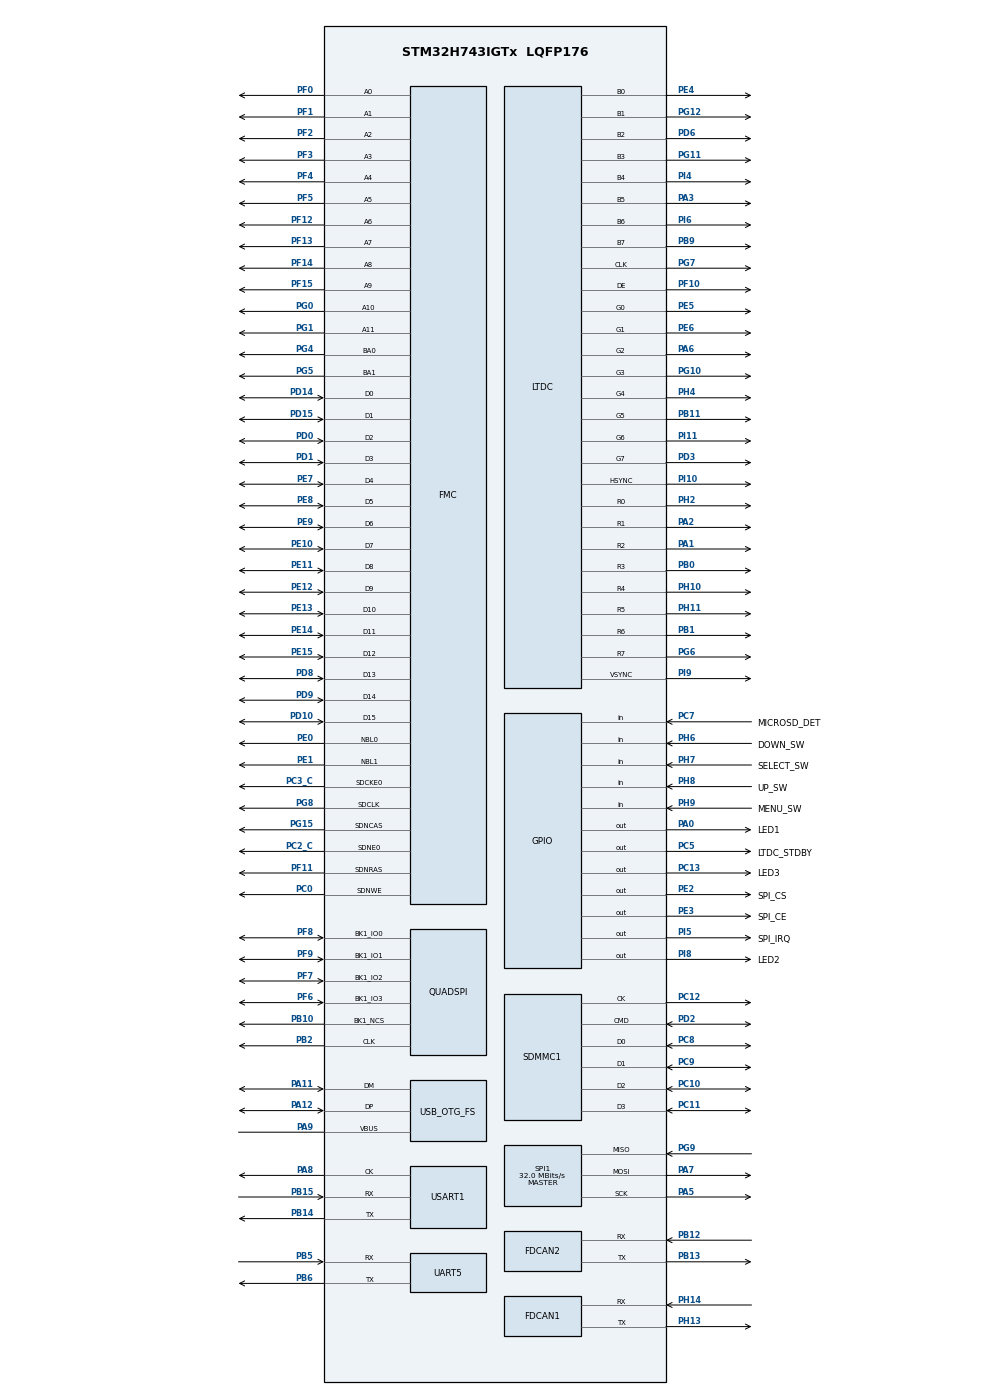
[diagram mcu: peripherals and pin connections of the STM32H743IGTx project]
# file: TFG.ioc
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CORTEX_M7.AccessPermission_S-Cortex_Memory_Protection_Unit_Region1_Settings_S=MPU_REGION_FULL_ACCESS
CORTEX_M7.AccessPermission_S-Cortex_Memory_Protection_Unit_Region2_Settings_S=MPU_REGION_FULL_ACCESS
CORTEX_M7.AccessPermission_S-Cortex_Memory_Protection_Unit_Region3_Settings_S=MPU_REGION_FULL_ACCESS
CORTEX_M7.BaseAddress_S-Cortex_Memory_Protection_Unit_Region1_Settings_S=0x90000000
CORTEX_M7.BaseAddress_S-Cortex_Memory_Protection_Unit_Region2_Settings_S=0xC0000000
CORTEX_M7.BaseAddress_S-Cortex_Memory_Protection_Unit_Region3_Settings_S=0xC0000000
CORTEX_M7.CPU_DCache=Enabled
CORTEX_M7.CPU_ICache=Enabled
CORTEX_M7.DisableExec_S-Cortex_Memory_Protection_Unit_Region1_Settings_S=MPU_INSTRUCTION_ACCESS_DISABLE
CORTEX_M7.DisableExec_S-Cortex_Memory_Protection_Unit_Region2_Settings_S=MPU_INSTRUCTION_ACCESS_DISABLE
CORTEX_M7.DisableExec_S-Cortex_Memory_Protection_Unit_Region3_Settings_S=MPU_INSTRUCTION_ACCESS_DISABLE
CORTEX_M7.Enable_S-Cortex_Memory_Protection_Unit_Region1_Settings_S=MPU_REGION_ENABLE
CORTEX_M7.Enable_S-Cortex_Memory_Protection_Unit_Region2_Settings_S=MPU_REGION_ENABLE
CORTEX_M7.Enable_S-Cortex_Memory_Protection_Unit_Region3_Settings_S=MPU_REGION_ENABLE
CORTEX_M7.IsCacheable_S-Cortex_Memory_Protection_Unit_Region1_Settings_S=MPU_ACCESS_CACHEABLE
CORTEX_M7.IsCacheable_S-Cortex_Memory_Protection_Unit_Region2_Settings_S=MPU_ACCESS_CACHEABLE
CORTEX_M7.IsCacheable_S-Cortex_Memory_Protection_Unit_Region3_Settings_S=MPU_ACCESS_NOT_CACHEABLE
CORTEX_M7.IsShareable_S-Cortex_Memory_Protection_Unit_Region3_Settings_S=MPU_ACCESS_SHAREABLE
CORTEX_M7.Size_S-Cortex_Memory_Protection_Unit_Region1_Settings_S=MPU_REGION_SIZE_256MB
CORTEX_M7.Size_S-Cortex_Memory_Protection_Unit_Region2_Settings_S=MPU_REGION_SIZE_32MB
CORTEX_M7.Size_S-Cortex_Memory_Protection_Unit_Region3_Settings_S=MPU_REGION_SIZE_2MB
CORTEX_M7.SubRegionDisable_S-Cortex_Memory_Protection_Unit_Region1_Settings_S=0x00
CORTEX_M7.default_mode_Activation=1
DMA2D.ColorMode=DMA2D_OUTPUT_RGB565
DMA2D.Mode=DMA2D_M2M
FDCAN1.CalculateBaudRateNominal=500000
FDCAN1.CalculateTimeBitNominal=2000
FDCAN1.CalculateTimeQuantumNominal=125.0
FDCAN1.NominalPrescaler=3
FDCAN1.NominalTimeSeg1=13
FDCAN1.NominalTimeSeg2=2
FDCAN2.AutoRetransmission=ENABLE
FDCAN2.CalculateBaudRateNominal=500000
FDCAN2.CalculateTimeBitNominal=2000
FDCAN2.CalculateTimeQuantumNominal=125.0
FDCAN2.ClockCalibrationCCU=DISABLE
FDCAN2.ExtFiltersNbr=1
FDCAN2.NominalPrescaler=3
FDCAN2.NominalTimeSeg1=13
FDCAN2.NominalTimeSeg2=2
FDCAN2.RxFifo0ElmtsNbr=32
FDCAN2.RxFifo1ElmtsNbr=32
FDCAN2.StdFiltersNbr=2
FDCAN2.TxFifoQueueElmtsNbr=32
FMC.CASLatency1=FMC_SDRAM_CAS_LATENCY_3
FMC.ExitSelfRefreshDelay1=5
FMC.LoadToActiveDelay1=2
FMC.RCDDelay1=2
FMC.RPDelay1=2
FMC.RPDelay2=2
FMC.ReadBurst1=FMC_SDRAM_RBURST_ENABLE
FMC.ReadBurst2=FMC_SDRAM_RBURST_ENABLE
FMC.ReadPipeDelay1=FMC_SDRAM_RPIPE_DELAY_1
FMC.ReadPipeDelay2=FMC_SDRAM_RPIPE_DELAY_1
FMC.RowCycleDelay1=3
FMC.RowCycleDelay2=3
FMC.SDClockPeriod1=FMC_SDRAM_CLOCK_PERIOD_2
FMC.SDClockPeriod2=FMC_SDRAM_CLOCK_PERIOD_2
FMC.SelfRefreshTime1=3
FMC.WriteRecoveryTime1=2
FREERTOS.Tasks01=defaultTask,24,4096,StartDefaultTask,Default,NULL,Dynamic,NULL,NULL;TouchGFXTask,24,4096,TouchGFX_Task,As external,NULL,Dynamic,NULL,NULL
FREERTOS.configTOTAL_HEAP_SIZE=65536
LTDC.ActiveW=800
LTDC.Alpha0_L0=0
LTDC.Alpha_L0=255
LTDC.DEPolarity=LTDC_DEPOLARITY_AH
LTDC.FBStartAdress_L0=0xC0000000
LTDC.HBP=10
LTDC.HFP=246
LTDC.HSync=1
LTDC.ImageHeight_L0=480
LTDC.ImageWidth_L0=800
LTDC.Layers=0
LTDC.PCPolarity=LTDC_PCPOLARITY_IPC
LTDC.PixelFormat_L0=LTDC_PIXEL_FORMAT_RGB565
LTDC.VBP=10
LTDC.VFP=35
LTDC.VSync=1
LTDC.WindowX0_L0=0
LTDC.WindowX1_L0=800
LTDC.WindowY0_L0=0
LTDC.WindowY1_L0=480
Mcu.Family=STM32H7
Mcu.Name=STM32H743IGTx
Mcu.Package=LQFP176
NVIC.DMA2D_IRQn=true\:9\:0\:true\:false\:true\:true\:true\:true\:true
NVIC.FDCAN2_IT0_IRQn=true\:5\:0\:false\:false\:true\:true\:true\:true\:true
NVIC.LTDC_IRQn=true\:9\:0\:true\:false\:true\:true\:true\:true\:true
NVIC.PriorityGroup=NVIC_PRIORITYGROUP_4
PA0.GPIO_Label=LED1
PA0.Signal=GPIO_Output
PA1.Mode=RGB888
PA1.Signal=LTDC_R2
PA11.Mode=Device_Only
PA11.Signal=USB_OTG_FS_DM
PA12.Mode=Device_Only
PA12.Signal=USB_OTG_FS_DP
PA13\ (JTMS/SWDIO).Mode=Serial_Wire
PA13\ (JTMS/SWDIO).Signal=DEBUG_JTMS-SWDIO
PA14\ (JTCK/SWCLK).Mode=Serial_Wire
PA14\ (JTCK/SWCLK).Signal=DEBUG_JTCK-SWCLK
PA2.Mode=RGB888
PA2.Signal=LTDC_R1
PA3.Mode=RGB888
PA3.Signal=LTDC_B5
PA5.Mode=Full_Duplex_Master
PA5.Signal=SPI1_SCK
PA6.Mode=RGB888
PA6.Signal=LTDC_G2
PA7.Mode=Full_Duplex_Master
PA7.Signal=SPI1_MOSI
PA8.Mode=Synchronous
PA8.Signal=USART1_CK
PA9.Mode=Activate_VBUS
PA9.Signal=USB_OTG_FS_VBUS
PB0.Mode=RGB888
PB0.Signal=LTDC_R3
PB1.Mode=RGB888
PB1.Signal=LTDC_R6
PB10.Mode=Single Bank 1
PB10.Signal=QUADSPI_BK1_NCS
PB11.Mode=RGB888
PB11.Signal=LTDC_G5
PB12.Mode=FDCAN_Activate
PB12.Signal=FDCAN2_RX
PB13.Mode=FDCAN_Activate
PB13.Signal=FDCAN2_TX
PB14.Mode=Synchronous
PB14.Signal=USART1_TX
PB15.Mode=Synchronous
PB15.Signal=USART1_RX
PB2.Mode=Single Bank 1
PB2.Signal=QUADSPI_CLK
PB5.Mode=Asynchronous
PB5.Signal=UART5_RX
PB6.Mode=Asynchronous
PB6.Signal=UART5_TX
PB9.Mode=RGB888
PB9.Signal=LTDC_B7
PC0.Signal=FMC_SDNWE
PC10.Mode=SD_4_bits_Wide_bus
PC10.Signal=SDMMC1_D2
PC11.Mode=SD_4_bits_Wide_bus
PC11.Signal=SDMMC1_D3
PC12.Mode=SD_4_bits_Wide_bus
PC12.Signal=SDMMC1_CK
PC13.GPIO_Label=LED3
PC13.Signal=GPIO_Output
PC2_C.Mode=SdramChipSelect1_1
PC2_C.Signal=FMC_SDNE0
PC3_C.Mode=SdramChipSelect1_1
PC3_C.Signal=FMC_SDCKE0
PC5.GPIO_Label=LTDC_STDBY
PC5.Signal=GPIO_Output
PC7.GPIO_Label=MICROSD_DET
PC7.Signal=GPIO_Input
PC8.Mode=SD_4_bits_Wide_bus
PC8.Signal=SDMMC1_D0
PC9.Mode=SD_4_bits_Wide_bus
PC9.Signal=SDMMC1_D1
PD0.Signal=FMC_D2_DA2
PD1.Signal=FMC_D3_DA3
PD10.Signal=FMC_D15_DA15
PD14.Signal=FMC_D0_DA0
PD15.Signal=FMC_D1_DA1
PD2.Mode=SD_4_bits_Wide_bus
PD2.Signal=SDMMC1_CMD
PD3.Mode=RGB888
PD3.Signal=LTDC_G7
PD6.Mode=RGB888
PD6.Signal=LTDC_B2
PD8.Signal=FMC_D13_DA13
PD9.Signal=FMC_D14_DA14
PE0.Signal=FMC_NBL0
PE1.Signal=FMC_NBL1
PE10.Signal=FMC_D7_DA7
PE11.Signal=FMC_D8_DA8
PE12.Signal=FMC_D9_DA9
PE13.Signal=FMC_D10_DA10
PE14.Signal=FMC_D11_DA11
PE15.Signal=FMC_D12_DA12
PE2.GPIO_Label=SPI_CS
PE2.Signal=GPIO_Output
PE3.GPIO_Label=SPI_CE
PE3.Signal=GPIO_Output
PE4.Mode=RGB888
PE4.Signal=LTDC_B0
PE5.Mode=RGB888
PE5.Signal=LTDC_G0
PE6.Mode=RGB888
PE6.Signal=LTDC_G1
PE7.Signal=FMC_D4_DA4
PE8.Signal=FMC_D5_DA5
PE9.Signal=FMC_D6_DA6
PF0.Signal=FMC_A0
PF1.Signal=FMC_A1
PF10.Mode=RGB888
PF10.Signal=LTDC_DE
PF11.Signal=FMC_SDNRAS
PF12.Signal=FMC_A6
PF13.Signal=FMC_A7
PF14.Signal=FMC_A8
PF15.Signal=FMC_A9
PF2.Signal=FMC_A2
PF3.Signal=FMC_A3
PF4.Signal=FMC_A4
PF5.Signal=FMC_A5
PF6.Mode=Single Bank 1
PF6.Signal=QUADSPI_BK1_IO3
PF7.Mode=Single Bank 1
PF7.Signal=QUADSPI_BK1_IO2
PF8.Mode=Single Bank 1
PF8.Signal=QUADSPI_BK1_IO0
PF9.Mode=Single Bank 1
PF9.Signal=QUADSPI_BK1_IO1
PG0.Signal=FMC_A10
PG1.Signal=FMC_A11
PG10.Mode=RGB888
PG10.Signal=LTDC_G3
PG11.Mode=RGB888
PG11.Signal=LTDC_B3
PG12.Mode=RGB888
PG12.Signal=LTDC_B1
PG15.Signal=FMC_SDNCAS
PG4.Signal=FMC_A14_BA0
PG5.Signal=FMC_A15_BA1
PG6.Mode=RGB888
PG6.Signal=LTDC_R7
PG7.Mode=RGB888
PG7.Signal=LTDC_CLK
PG8.Signal=FMC_SDCLK
PG9.Mode=Full_Duplex_Master
PG9.Signal=SPI1_MISO
PH0-OSC_IN\ (PH0).Mode=HSE-External-Oscillator
PH0-OSC_IN\ (PH0).Signal=RCC_OSC_IN
PH1-OSC_OUT\ (PH1).Mode=HSE-External-Oscillator
PH1-OSC_OUT\ (PH1).Signal=RCC_OSC_OUT
PH10.Mode=RGB888
PH10.Signal=LTDC_R4
PH11.Mode=RGB888
PH11.Signal=LTDC_R5
PH13.Mode=FDCAN_Activate
PH13.Signal=FDCAN1_TX
PH14.Mode=FDCAN_Activate
PH14.Signal=FDCAN1_RX
PH2.Mode=RGB888
PH2.Signal=LTDC_R0
PH4.Mode=RGB888
PH4.Signal=LTDC_G4
PH6.GPIO_Label=DOWN_SW
PH6.GPIO_PuPd=GPIO_PULLDOWN
PH6.Signal=GPIO_Input
PH7.GPIO_Label=SELECT_SW
PH7.GPIO_PuPd=GPIO_PULLDOWN
PH7.Signal=GPIO_Input
PH8.GPIO_Label=UP_SW
PH8.GPIO_PuPd=GPIO_PULLDOWN
PH8.Signal=GPIO_Input
PH9.GPIO_Label=MENU_SW
PH9.GPIO_PuPd=GPIO_PULLDOWN
PH9.Signal=GPIO_Input
PI10.Mode=RGB888
PI10.Signal=LTDC_HSYNC
PI11.Mode=RGB888
PI11.Signal=LTDC_G6
PI4.Mode=RGB888
PI4.Signal=LTDC_B4
PI5.GPIO_Label=SPI_IRQ
PI5.Signal=GPIO_Output
PI6.Mode=RGB888
PI6.Signal=LTDC_B6
PI8.GPIO_Label=LED2
PI8.Signal=GPIO_Output
PI9.Mode=RGB888
PI9.Signal=LTDC_VSYNC
ProjectManager.HeapSize=0x200
ProjectManager.StackSize=0x400
ProjectManager.TargetToolchain=STM32CubeIDE
QUADSPI.ChipSelectHighTime=QSPI_CS_HIGH_TIME_2_CYCLE
QUADSPI.ClockPrescaler=3
QUADSPI.FifoThreshold=4
QUADSPI.FlashSize=23
RCC.ADCFreq_Value=129000000
RCC.APB1Freq_Value=60000000
RCC.APB2Freq_Value=60000000
RCC.APB3Freq_Value=60000000
RCC.APB4Freq_Value=60000000
RCC.CortexFreq_Value=240000000
RCC.D1PPRE=RCC_APB3_DIV2
RCC.D2PPRE1=RCC_APB1_DIV2
RCC.D2PPRE2=RCC_APB2_DIV2
RCC.D3PPRE=RCC_APB4_DIV2
RCC.DIVM1=8
RCC.DIVM3=4
RCC.DIVN1=60
RCC.DIVN3=20
RCC.DIVQ1=4
RCC.DIVR2=6
RCC.DIVR3=11
RCC.HCLKFreq_Value=120000000
RCC.HPRE=RCC_HCLK_DIV2
RCC.HSE_VALUE=24000000
RCC.PLL2FRACN=0
RCC.PLL3FRACN=0
RCC.PLLFRACN=0
RCC.SDMMC1CLockSelection=RCC_SDMMCCLKSOURCE_PLL2
RCC.SPI123CLockSelection=RCC_SPI123CLKSOURCE_CLKP
RCC.SYSCLKFreq_VALUE=240000000
RCC.SYSCLKSource=RCC_SYSCLKSOURCE_PLLCLK
RCC.USART16CLockSelection=RCC_USART16CLKSOURCE_CSI
RCC.USART234578CLockSelection=RCC_USART234578CLKSOURCE_CSI
RCC.USBCLockSelection=RCC_USBCLKSOURCE_HSI48
RCC.USBFreq_Value=48000000
SDMMC1.ClockDiv=2
SH.FMC_A0.0=FMC_A0,12b-sda1
SH.FMC_A1.0=FMC_A1,12b-sda1
SH.FMC_A10.0=FMC_A10,12b-sda1
SH.FMC_A11.0=FMC_A11,12b-sda1
SH.FMC_A14_BA0.0=FMC_BA0,FourSdramBanks1
SH.FMC_A15_BA1.0=FMC_BA1,FourSdramBanks1
SH.FMC_A2.0=FMC_A2,12b-sda1
SH.FMC_A3.0=FMC_A3,12b-sda1
SH.FMC_A4.0=FMC_A4,12b-sda1
SH.FMC_A5.0=FMC_A5,12b-sda1
SH.FMC_A6.0=FMC_A6,12b-sda1
SH.FMC_A7.0=FMC_A7,12b-sda1
SH.FMC_A8.0=FMC_A8,12b-sda1
SH.FMC_A9.0=FMC_A9,12b-sda1
SH.FMC_D0_DA0.0=FMC_D0,sd-16b-d1
SH.FMC_D10_DA10.0=FMC_D10,sd-16b-d1
SH.FMC_D11_DA11.0=FMC_D11,sd-16b-d1
SH.FMC_D12_DA12.0=FMC_D12,sd-16b-d1
SH.FMC_D13_DA13.0=FMC_D13,sd-16b-d1
SH.FMC_D14_DA14.0=FMC_D14,sd-16b-d1
SH.FMC_D15_DA15.0=FMC_D15,sd-16b-d1
SH.FMC_D1_DA1.0=FMC_D1,sd-16b-d1
SH.FMC_D2_DA2.0=FMC_D2,sd-16b-d1
SH.FMC_D3_DA3.0=FMC_D3,sd-16b-d1
SH.FMC_D4_DA4.0=FMC_D4,sd-16b-d1
SH.FMC_D5_DA5.0=FMC_D5,sd-16b-d1
SH.FMC_D6_DA6.0=FMC_D6,sd-16b-d1
SH.FMC_D7_DA7.0=FMC_D7,sd-16b-d1
SH.FMC_D8_DA8.0=FMC_D8,sd-16b-d1
SH.FMC_D9_DA9.0=FMC_D9,sd-16b-d1
SH.FMC_NBL0.0=FMC_NBL0,Sd2ByteEnable1
SH.FMC_NBL1.0=FMC_NBL1,Sd2ByteEnable1
SH.FMC_SDCLK.0=FMC_SDCLK,12b-sda1
SH.FMC_SDNCAS.0=FMC_SDNCAS,12b-sda1
SH.FMC_SDNRAS.0=FMC_SDNRAS,12b-sda1
SH.FMC_SDNWE.0=FMC_SDNWE,12b-sda1
SPI1.CalculateBaudRate=32.0 MBits/s
SPI1.Direction=SPI_DIRECTION_2LINES
SPI1.Mode=SPI_MODE_MASTER
SPI1.VirtualType=VM_MASTER
STMicroelectronics.X-CUBE-TOUCHGFX.4.25.0.ApplicationCcGraphicsJjApplication=TouchGFXOoGenerator
STMicroelectronics.X-CUBE-TOUCHGFX.4.25.0.tgfx_buffering_strategy=Double
STMicroelectronics.X-CUBE-TOUCHGFX.4.25.0.tgfx_display_interface=disp_ltdc
STMicroelectronics.X-CUBE-TOUCHGFX.4.25.0.tgfx_hardware_accelerator=dma_2d
STMicroelectronics.X-CUBE-TOUCHGFX.4.25.0.tgfx_vsync=vsync_ltdc
STMicroelectronics.X-CUBE-TOUCHGFX.4.25.0_IsPackSelfContextualization=true
USART1.VirtualMode-Synchronous=VM_SYNC
USB_OTG_FS.VirtualMode=Device_Only
VP_CRC_VS_CRC.Mode=CRC_Activate
VP_DMA2D_VS_DMA2D.Mode=DMA2D_Activate
VP_FATFS_VS_SDIO.Mode=SDIO
VP_FREERTOS_VS_CMSIS_V2.Mode=CMSIS_V2
VP_JPEG_VS_JPEG.Mode=JPEG_Activate
VP_MEMORYMAP_VS_MEMORYMAP.Mode=CurAppReg
VP_STMicroelectronics.X-CUBE-TOUCHGFX_VS_GraphicsJjApplication_4.25.0.Mode=GraphicsJjApplication
board=custom

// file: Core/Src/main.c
/* USER CODE BEGIN Header */
/**
  ******************************************************************************
  * @file           : main.c
  * @brief          : Main program body
  ******************************************************************************
  * @attention
  *
  * Copyright (c) 2026 STMicroelectronics.
  * All rights reserved.
  *
  * This software is licensed under terms that can be found in the LICENSE file
  * in the root directory of this software component.
  * If no LICENSE file comes with this software, it is provided AS-IS.
  *
  ******************************************************************************
  */
/* USER CODE END Header */
#include "main.h"
#include "cmsis_os.h"
#include "crc.h"
#include "dma2d.h"
#include "fatfs.h"
#include "fdcan.h"
#include "jpeg.h"
#include "ltdc.h"
#include "memorymap.h"
#include "quadspi.h"
#include "sdmmc.h"
#include "spi.h"
#include "usart.h"
#include "usb_otg.h"
#include "gpio.h"
#include "fmc.h"
#include "app_touchgfx.h"
#include <stdio.h>

/* USER CODE BEGIN Includes */
#include <string.h>

extern uint8_t ltdc_init_ok;
extern uint8_t ltdc_init_fail_step;
extern uint8_t sdmmc1_init_ok;
volatile uint8_t g_sd_preos_done = 0U;
volatile uint8_t g_sd_preos_ok = 0U;

/* USER CODE END Includes */

/* USER CODE BEGIN PD */
#define QSPI_CMD_JEDEC_ID                ((uint8_t)0x9F)
#define QSPI_CMD_READ_DATA               ((uint8_t)0x03)
#define QSPI_CMD_FAST_READ               ((uint8_t)0x0B)
#define QSPI_CMD_WRITE_ENABLE            ((uint8_t)0x06)
#define QSPI_CMD_READ_STATUS_REG         ((uint8_t)0x05)
#define QSPI_CMD_PAGE_PROGRAM            ((uint8_t)0x02)
#define QSPI_CMD_SECTOR_ERASE_4K         ((uint8_t)0x20)
#define QSPI_STATUS_WIP                  ((uint8_t)0x01)
#define QSPI_STATUS_WEL                  ((uint8_t)0x02)
#define MT25QL128_JEDEC_MFR              ((uint8_t)0x20)
#define MT25QL128_JEDEC_TYPE             ((uint8_t)0xBA)
#define MT25QL128_JEDEC_CAP              ((uint8_t)0x18)
#define QSPI_TIMEOUT_MS                  ((uint32_t)2000U)
#define QSPI_SECTOR_SIZE                 ((uint32_t)4096U)
#define QSPI_PAGE_SIZE                   ((uint32_t)256U)

#define LCD_WIDTH                        ((uint32_t)800U)
#define LCD_HEIGHT                       ((uint32_t)480U)
#define LCD_BPP_BYTES                    ((uint32_t)2U)
#define LCD_FB_SIZE_BYTES                (LCD_WIDTH * LCD_HEIGHT * LCD_BPP_BYTES)
#define LCD_FB_ADDRESS                   ((uint32_t)0xC0000000U)
#define LCD_FB_ADDRESS_ALT               (LCD_FB_ADDRESS + LCD_FB_SIZE_BYTES)
#define LCD_FB_MPU_REGION_SIZE           MPU_REGION_SIZE_2MB
#define LTDC_FORCE_DIRECT_RED_FRAME      0U

/* USER CODE END PD */

/* USER CODE BEGIN PV */
uint8_t qspi_test_ok = 0U;
uint8_t ltdc_fail_code = 0U;
uint8_t touchgfx_assets_ok = 0U;

/* USER CODE END PV */

void SystemClock_Config(void);
void PeriphCommonClock_Config(void);
static void MPU_Config(void);
void MX_FREERTOS_Init(void);
/* USER CODE BEGIN PFP */
static uint8_t QSPI_QuickTest(void);
static uint8_t QSPI_WriteEnable(void);
static uint8_t QSPI_WaitReady(uint32_t timeout_ms);
static uint8_t QSPI_Read(uint32_t address, uint8_t *buffer, uint32_t length);
static uint8_t QSPI_PageProgram(uint32_t address, const uint8_t *buffer, uint32_t length);
static uint8_t QSPI_SectorErase(uint32_t address);
static uint8_t QSPI_ProgramBuffer(uint32_t address, const uint8_t *buffer, uint32_t length);
static uint8_t QSPI_EnableMemoryMappedMode(void);
static uint8_t TouchGFX_AssetsPresent(void);
static void TouchGFX_LogAssetProbe(void);

/* USER CODE END PFP */

/* USER CODE BEGIN 0 */
static uint8_t qspi_backup_sector[QSPI_SECTOR_SIZE];
static uint8_t qspi_test_pattern[QSPI_PAGE_SIZE];
static uint8_t qspi_verify_page[QSPI_PAGE_SIZE];
extern uint8_t __extflash_start__;
extern uint8_t __extflash_end__;

__attribute__((weak)) void MX_FATFS_Init(void)
{
}

__attribute__((weak)) void MX_TouchGFX_Init(void)
{
}

__attribute__((weak)) void MX_TouchGFX_PreOSInit(void)
{
}

__attribute__((weak)) osStatus_t osKernelInitialize(void)
{
  return osOK;
}

__attribute__((weak)) osStatus_t osKernelStart(void)
{
  return osOK;
}

__attribute__((weak)) void MX_FREERTOS_Init(void)
{
}

static uint8_t QSPI_WriteEnable(void)
{
  QSPI_CommandTypeDef s_command = {0};
  QSPI_AutoPollingTypeDef s_config = {0};

  s_command.InstructionMode = QSPI_INSTRUCTION_1_LINE;
  s_command.Instruction = QSPI_CMD_WRITE_ENABLE;
  s_command.AddressMode = QSPI_ADDRESS_NONE;
  s_command.AlternateByteMode = QSPI_ALTERNATE_BYTES_NONE;
  s_command.DataMode = QSPI_DATA_NONE;
  s_command.DummyCycles = 0;
  s_command.DdrMode = QSPI_DDR_MODE_DISABLE;
  s_command.DdrHoldHalfCycle = QSPI_DDR_HHC_ANALOG_DELAY;
  s_command.SIOOMode = QSPI_SIOO_INST_EVERY_CMD;

  if (HAL_QSPI_Command(&hqspi, &s_command, QSPI_TIMEOUT_MS) != HAL_OK)
  {
    return 0U;
  }

  s_command.Instruction = QSPI_CMD_READ_STATUS_REG;
  s_command.DataMode = QSPI_DATA_1_LINE;
  s_command.NbData = 1;

  s_config.Match = QSPI_STATUS_WEL;
  s_config.Mask = QSPI_STATUS_WEL;
  s_config.MatchMode = QSPI_MATCH_MODE_AND;
  s_config.StatusBytesSize = 1;
  s_config.Interval = 0x10;
  s_config.AutomaticStop = QSPI_AUTOMATIC_STOP_ENABLE;

  if (HAL_QSPI_AutoPolling(&hqspi, &s_command, &s_config, QSPI_TIMEOUT_MS) != HAL_OK)
  {
    return 0U;
  }

  return 1U;
}

static uint8_t QSPI_WaitReady(uint32_t timeout_ms)
{
  QSPI_CommandTypeDef s_command = {0};
  QSPI_AutoPollingTypeDef s_config = {0};

  s_command.InstructionMode = QSPI_INSTRUCTION_1_LINE;
  s_command.Instruction = QSPI_CMD_READ_STATUS_REG;
  s_command.AddressMode = QSPI_ADDRESS_NONE;
  s_command.AlternateByteMode = QSPI_ALTERNATE_BYTES_NONE;
  s_command.DataMode = QSPI_DATA_1_LINE;
  s_command.DummyCycles = 0;
  s_command.NbData = 1;
  s_command.DdrMode = QSPI_DDR_MODE_DISABLE;
  s_command.DdrHoldHalfCycle = QSPI_DDR_HHC_ANALOG_DELAY;
  s_command.SIOOMode = QSPI_SIOO_INST_EVERY_CMD;

  s_config.Match = 0;
  s_config.Mask = QSPI_STATUS_WIP;
  s_config.MatchMode = QSPI_MATCH_MODE_AND;
  s_config.StatusBytesSize = 1;
  s_config.Interval = 0x10;
  s_config.AutomaticStop = QSPI_AUTOMATIC_STOP_ENABLE;

  if (HAL_QSPI_AutoPolling(&hqspi, &s_command, &s_config, timeout_ms) != HAL_OK)
  {
    return 0U;
  }

  return 1U;
}

static uint8_t QSPI_Read(uint32_t address, uint8_t *buffer, uint32_t length)
{
  QSPI_CommandTypeDef s_command = {0};

  s_command.InstructionMode = QSPI_INSTRUCTION_1_LINE;
  s_command.Instruction = QSPI_CMD_READ_DATA;
  s_command.AddressMode = QSPI_ADDRESS_1_LINE;
  s_command.AddressSize = QSPI_ADDRESS_24_BITS;
  s_command.Address = address;
  s_command.AlternateByteMode = QSPI_ALTERNATE_BYTES_NONE;
  s_command.DataMode = QSPI_DATA_1_LINE;
  s_command.DummyCycles = 0;
  s_command.NbData = length;
  s_command.DdrMode = QSPI_DDR_MODE_DISABLE;
  s_command.DdrHoldHalfCycle = QSPI_DDR_HHC_ANALOG_DELAY;
  s_command.SIOOMode = QSPI_SIOO_INST_EVERY_CMD;

  if (HAL_QSPI_Command(&hqspi, &s_command, QSPI_TIMEOUT_MS) != HAL_OK)
  {
    return 0U;
  }

  if (HAL_QSPI_Receive(&hqspi, buffer, QSPI_TIMEOUT_MS) != HAL_OK)
  {
    return 0U;
  }

  return 1U;
}

static uint8_t QSPI_PageProgram(uint32_t address, const uint8_t *buffer, uint32_t length)
{
  QSPI_CommandTypeDef s_command = {0};

  if ((length == 0U) || (length > QSPI_PAGE_SIZE))
  {
    return 0U;
  }

  if (QSPI_WriteEnable() == 0U)
  {
    return 0U;
  }

  s_command.InstructionMode = QSPI_INSTRUCTION_1_LINE;
  s_command.Instruction = QSPI_CMD_PAGE_PROGRAM;
  s_command.AddressMode = QSPI_ADDRESS_1_LINE;
  s_command.AddressSize = QSPI_ADDRESS_24_BITS;
  s_command.Address = address;
  s_command.AlternateByteMode = QSPI_ALTERNATE_BYTES_NONE;
  s_command.DataMode = QSPI_DATA_1_LINE;
  s_command.DummyCycles = 0;
  s_command.NbData = length;
  s_command.DdrMode = QSPI_DDR_MODE_DISABLE;
  s_command.DdrHoldHalfCycle = QSPI_DDR_HHC_ANALOG_DELAY;
  s_command.SIOOMode = QSPI_SIOO_INST_EVERY_CMD;

  if (HAL_QSPI_Command(&hqspi, &s_command, QSPI_TIMEOUT_MS) != HAL_OK)
  {
    return 0U;
  }

  if (HAL_QSPI_Transmit(&hqspi, (uint8_t *)buffer, QSPI_TIMEOUT_MS) != HAL_OK)
  {
    return 0U;
  }

  return QSPI_WaitReady(QSPI_TIMEOUT_MS);
}

static uint8_t QSPI_SectorErase(uint32_t address)
{
  QSPI_CommandTypeDef s_command = {0};

  if (QSPI_WriteEnable() == 0U)
  {
    return 0U;
  }

  s_command.InstructionMode = QSPI_INSTRUCTION_1_LINE;
  s_command.Instruction = QSPI_CMD_SECTOR_ERASE_4K;
  s_command.AddressMode = QSPI_ADDRESS_1_LINE;
  s_command.AddressSize = QSPI_ADDRESS_24_BITS;
  s_command.Address = address;
  s_command.AlternateByteMode = QSPI_ALTERNATE_BYTES_NONE;
  s_command.DataMode = QSPI_DATA_NONE;
  s_command.DummyCycles = 0;
  s_command.DdrMode = QSPI_DDR_MODE_DISABLE;
  s_command.DdrHoldHalfCycle = QSPI_DDR_HHC_ANALOG_DELAY;
  s_command.SIOOMode = QSPI_SIOO_INST_EVERY_CMD;

  if (HAL_QSPI_Command(&hqspi, &s_command, QSPI_TIMEOUT_MS) != HAL_OK)
  {
    return 0U;
  }

  return QSPI_WaitReady(8000U);
}

static uint8_t QSPI_ProgramBuffer(uint32_t address, const uint8_t *buffer, uint32_t length)
{
  uint32_t offset = 0U;
  uint32_t chunk = 0U;

  while (offset < length)
  {
    chunk = length - offset;
    if (chunk > QSPI_PAGE_SIZE)
    {
      chunk = QSPI_PAGE_SIZE;
    }

    if (QSPI_PageProgram(address + offset, &buffer[offset], chunk) == 0U)
    {
      return 0U;
    }

    offset += chunk;
  }

  return 1U;
}

static uint8_t QSPI_QuickTest(void)
{
  QSPI_CommandTypeDef s_command = {0};
  uint8_t jedec_id[3] = {0};
  uint32_t flash_size_bytes = 0U;
  uint32_t test_sector_addr = 0U;

  s_command.InstructionMode = QSPI_INSTRUCTION_1_LINE;
  s_command.Instruction = 0x9FU;
  s_command.AddressMode = QSPI_ADDRESS_NONE;
  s_command.AlternateByteMode = QSPI_ALTERNATE_BYTES_NONE;
  s_command.DataMode = QSPI_DATA_1_LINE;
  s_command.DummyCycles = 0;
  s_command.NbData = 3;
  s_command.DdrMode = QSPI_DDR_MODE_DISABLE;
  s_command.DdrHoldHalfCycle = QSPI_DDR_HHC_ANALOG_DELAY;
  s_command.SIOOMode = QSPI_SIOO_INST_EVERY_CMD;

  if (HAL_QSPI_Command(&hqspi, &s_command, 1000U) != HAL_OK)
  {
    return 0U;
  }

  if (HAL_QSPI_Receive(&hqspi, jedec_id, 1000U) != HAL_OK)
  {
    return 0U;
  }

  if ((jedec_id[0] == 0x00U) || (jedec_id[0] == 0xFFU))
  {
    return 0U;
  }

  if ((jedec_id[1] == 0x00U) && (jedec_id[2] == 0x00U))
  {
    return 0U;
  }

  if ((jedec_id[0] != MT25QL128_JEDEC_MFR) ||
      (jedec_id[1] != MT25QL128_JEDEC_TYPE) ||
      (jedec_id[2] != MT25QL128_JEDEC_CAP))
  {
    return 0U;
  }

  if ((jedec_id[2] < 0x10U) || (jedec_id[2] > 0x25U))
  {
    return 0U;
  }

  flash_size_bytes = (1UL << jedec_id[2]);
  if (flash_size_bytes < (QSPI_SECTOR_SIZE * 4U))
  {
    return 0U;
  }

  test_sector_addr = flash_size_bytes - (QSPI_SECTOR_SIZE * 2U);

  if (QSPI_Read(test_sector_addr, qspi_backup_sector, QSPI_SECTOR_SIZE) == 0U)
  {
    return 0U;
  }

  for (uint32_t i = 0U; i < QSPI_PAGE_SIZE; i++)
  {
    qspi_test_pattern[i] = (uint8_t)(i ^ 0x5AU);
  }

  if (QSPI_SectorErase(test_sector_addr) == 0U)
  {
    return 0U;
  }

  if (QSPI_PageProgram(test_sector_addr, qspi_test_pattern, QSPI_PAGE_SIZE) == 0U)
  {
    return 0U;
  }

  if (QSPI_Read(test_sector_addr, qspi_verify_page, QSPI_PAGE_SIZE) == 0U)
  {
    return 0U;
  }

  if (memcmp(qspi_test_pattern, qspi_verify_page, QSPI_PAGE_SIZE) != 0)
  {
    return 0U;
  }

  if (QSPI_SectorErase(test_sector_addr) == 0U)
  {
    return 0U;
  }

  if (QSPI_ProgramBuffer(test_sector_addr, qspi_backup_sector, QSPI_SECTOR_SIZE) == 0U)
  {
    return 0U;
  }

  return 1U;
}

static uint8_t QSPI_EnableMemoryMappedMode(void)
{
  QSPI_CommandTypeDef s_command = {0};
  QSPI_MemoryMappedTypeDef s_mem_mapped_cfg = {0};

  s_command.InstructionMode = QSPI_INSTRUCTION_1_LINE;
  s_command.Instruction = QSPI_CMD_FAST_READ;
  s_command.AddressMode = QSPI_ADDRESS_1_LINE;
  s_command.AddressSize = QSPI_ADDRESS_24_BITS;
  s_command.Address = 0U;
  s_command.AlternateByteMode = QSPI_ALTERNATE_BYTES_NONE;
  s_command.DataMode = QSPI_DATA_1_LINE;
  s_command.DummyCycles = 8;
  s_command.NbData = 0U;
  s_command.DdrMode = QSPI_DDR_MODE_DISABLE;
  s_command.DdrHoldHalfCycle = QSPI_DDR_HHC_ANALOG_DELAY;
  s_command.SIOOMode = QSPI_SIOO_INST_EVERY_CMD;

  s_mem_mapped_cfg.TimeOutActivation = QSPI_TIMEOUT_COUNTER_DISABLE;
  s_mem_mapped_cfg.TimeOutPeriod = 0U;

  if (HAL_QSPI_MemoryMapped(&hqspi, &s_command, &s_mem_mapped_cfg) != HAL_OK)
  {
    return 0U;
  }

  return 1U;
}

static uint8_t TouchGFX_AssetsPresent(void)
{
  volatile const uint8_t *ext = &__extflash_start__;
  uint32_t ext_size = (uint32_t)(&__extflash_end__ - &__extflash_start__);
  uint32_t sample = 0U;
  uint32_t non_ff = 0U;

  if (ext_size == 0U)
  {
    return 0U;
  }

  sample = (ext_size >= 256U) ? 256U : ext_size;

  for (uint32_t i = 0U; i < sample; i++)
  {
    if (ext[i] != 0xFFU)
    {
      non_ff++;
    }
  }

  return (non_ff > 8U) ? 1U : 0U;
}

static void TouchGFX_LogAssetProbe(void)
{
  volatile const uint8_t *ext = &__extflash_start__;
  uint32_t ext_size = (uint32_t)(&__extflash_end__ - &__extflash_start__);
  char buffer[192];

  if (huart5.gState == HAL_UART_STATE_RESET)
  {
    return;
  }

  if (ext_size < 16U)
  {
    (void)snprintf(buffer,
                   sizeof(buffer),
                   "[BOOT] extflash size=%lu bytes (too small for probe)\r\n",
                   (unsigned long)ext_size);
    Debug_LogUart5(buffer);
    return;
  }

  (void)snprintf(buffer,
                 sizeof(buffer),
                 "[BOOT] asset section @%08lX size=%lu sample=%02X %02X %02X %02X %02X %02X %02X %02X %02X %02X %02X %02X %02X %02X %02X %02X\r\n",
                 (unsigned long)ext,
                 (unsigned long)ext_size,
                 ext[0], ext[1], ext[2], ext[3],
                 ext[4], ext[5], ext[6], ext[7],
                 ext[8], ext[9], ext[10], ext[11],
                 ext[12], ext[13], ext[14], ext[15]);
  Debug_LogUart5(buffer);
}

  /* Disable D-Cache for a clean test — same approach as HW diagnostic */
/* USER CODE END 0 */

int main(void)
{

  /* USER CODE BEGIN 1 */
  /* ---- Raw LED init via registers (before HAL, before anything) ---- */
  /* LED1=PA0, LED2=PI8, LED3=PC13 */
  RCC->AHB4ENR |= RCC_AHB4ENR_GPIOAEN | RCC_AHB4ENR_GPIOCEN | RCC_AHB4ENR_GPIOIEN;
  __DSB(); __NOP(); __NOP();
  /* PA0 = output */
  GPIOA->MODER = (GPIOA->MODER & ~(3U << (0*2))) | (1U << (0*2));
  /* PC13 = output */
  GPIOC->MODER = (GPIOC->MODER & ~(3U << (13*2))) | (1U << (13*2));
  /* PI8 = output */
  GPIOI->MODER = (GPIOI->MODER & ~(3U << (8*2))) | (1U << (8*2));
  /* All LEDs OFF */
  GPIOA->BSRR = (1U << (0+16));  /* LED1 OFF */
  GPIOI->BSRR = (1U << (8+16));  /* LED2 OFF */
  GPIOC->BSRR = (1U << (13+16)); /* LED3 OFF */
  /* USER CODE END 1 */

  /* MPU Configuration--------------------------------------------------------*/
  MPU_Config();

  /* Enable the CPU Cache */

  /* Enable I-Cache---------------------------------------------------------*/
  SCB_EnableICache();

  /* Enable D-Cache---------------------------------------------------------*/
  SCB_EnableDCache();

  /* MCU Configuration--------------------------------------------------------*/

  /* Reset of all peripherals, Initializes the Flash interface and the Systick. */
  HAL_Init();

  /* USER CODE BEGIN Init */
  /* LED1 ON = HAL_Init passed */
  GPIOA->BSRR = (1U << 0);
  /* USER CODE END Init */

  /* Configure the system clock */
  Debug_SetStage(1U, NULL);
  SystemClock_Config();

  /* Configure the peripherals common clocks */
  Debug_SetStage(6U, NULL);
  PeriphCommonClock_Config();

  /* Initialize all configured peripherals */
  Debug_SetStage(7U, NULL);
  MX_GPIO_Init();
  Debug_SetStage(8U, "[BOOT] stage 8 GPIO ok\r\n");
  Debug_SetStage(9U, NULL);
  MX_UART5_Init();
  Debug_LogUart5("[BOOT] UART5 online\r\n");
  Debug_SetStage(10U, NULL);
  MX_DMA2D_Init();
  Debug_SetStage(11U, "[BOOT] stage 11 DMA2D ok\r\n");
  MX_FDCAN1_Init();
  Debug_SetStage(12U, "[BOOT] stage 12 FDCAN1 ok\r\n");
  MX_FDCAN2_Init();
  Debug_SetStage(13U, "[BOOT] stage 13 FDCAN2 ok\r\n");
  MX_FMC_Init();
  Debug_SetStage(14U, "[BOOT] stage 14 FMC ok\r\n");
  MX_JPEG_Init();
  Debug_SetStage(15U, "[BOOT] stage 15 JPEG ok\r\n");
  MX_LTDC_Init();
  Debug_SetStage(16U, "[BOOT] stage 16 LTDC ok\r\n");
  MX_QUADSPI_Init();
  Debug_SetStage(17U, "[BOOT] stage 17 QSPI ok\r\n");
  qspi_test_ok = QSPI_QuickTest();
  Debug_LogUart5((qspi_test_ok != 0U) ? "[BOOT] QSPI JEDEC quick test ok\r\n" : "[BOOT] QSPI JEDEC quick test fail\r\n");
  MX_SDMMC1_SD_Init();
  Debug_SetStage(18U, "[BOOT] stage 18 SDMMC ok\r\n");
  MX_USART1_Init();
  Debug_SetStage(19U, "[BOOT] stage 19 USART1 ok\r\n");
  Debug_LogUart5((HAL_SDRAM_GetState(&hsdram1) == HAL_SDRAM_STATE_READY) ? "[BOOT] SDRAM ready\r\n" : "[BOOT] SDRAM not ready\r\n");
  Debug_LogUart5((ltdc_init_ok != 0U) ? "[BOOT] LTDC init ok\r\n" : "[BOOT] LTDC init fail\r\n");
  Panel_ClearFramebuffers(0x00U, 0x00U, 0x00U);
  Debug_LogUart5("[BOOT] framebuffer cleared\r\n");
  Panel_ExitStandby();
#if (LTDC_FORCE_DIRECT_RED_FRAME != 0U)
  Panel_ClearFramebuffers(0xFFU, 0x00U, 0x00U);
  Debug_LogUart5("[BOOT] direct red frame mode\r\n");
  while (1)
  {
    HAL_Delay(1000U);
  }
#endif
  MX_USB_OTG_FS_PCD_Init();
  Debug_SetStage(11U, "[BOOT] stage 11 USB ok\r\n");
  MX_CRC_Init();
  Debug_SetStage(12U, "[BOOT] stage 12 CRC ok\r\n");
  MX_SPI1_Init();
  Debug_SetStage(13U, "[BOOT] stage 13 SPI1 ok\r\n");
  MX_FATFS_Init();
  Debug_SetStage(14U, "[BOOT] stage 14 FATFS ok\r\n");
  HAL_Delay(200U);

  /* Call PreOsInit function */
  Debug_LogUart5("[BOOT] TouchGFX PreOS init...\r\n");
  MX_TouchGFX_PreOSInit();
  Debug_SetStage(20U, "[BOOT] stage 20 PreOS ok\r\n");
  touchgfx_assets_ok = QSPI_EnableMemoryMappedMode();
  if (touchgfx_assets_ok != 0U)
  {
    TouchGFX_LogAssetProbe();
    touchgfx_assets_ok = TouchGFX_AssetsPresent();
  }
  Debug_LogUart5((touchgfx_assets_ok != 0U) ? "[BOOT] asset section present\r\n" : "[BOOT] asset section not detected\r\n");
  Debug_LogUart5("[BOOT] TouchGFX init...\r\n");
  MX_TouchGFX_Init();
  Debug_SetStage(21U, "[BOOT] stage 21 TouchGFX init ok\r\n");
  Debug_LogUart5("[BOOT] TouchGFX init returned\r\n");

  /* Init scheduler */
  Debug_LogUart5("[BOOT] osKernelInitialize\r\n");
  osKernelInitialize();
  Debug_SetStage(22U, "[BOOT] stage 22 kernel init ok\r\n");

  /* Call init function for freertos objects (in cmsis_os2.c) */
  MX_FREERTOS_Init();
  Debug_SetStage(23U, "[BOOT] stage 23 freertos objects ok\r\n");

  /* Start scheduler */
  Debug_LogUart5("[BOOT] starting scheduler\r\n");
  Debug_SetRuntimeLogsEnabled(0U);
  Debug_SetStage(24U, NULL);
  osKernelStart();

  /* We should never get here as control is now taken by the scheduler */

  /* Infinite loop */
  while (1)
  {

  }
}

void SystemClock_Config(void)
{
  RCC_OscInitTypeDef RCC_OscInitStruct = {0};
  RCC_ClkInitTypeDef RCC_ClkInitStruct = {0};

  Debug_SetStage(2U, NULL);

  /** Supply configuration update enable
  */
  HAL_PWREx_ConfigSupply(PWR_LDO_SUPPLY);

  /** Configure the main internal regulator output voltage
  */
  __HAL_PWR_VOLTAGESCALING_CONFIG(PWR_REGULATOR_VOLTAGE_SCALE1);

  while(!__HAL_PWR_GET_FLAG(PWR_FLAG_VOSRDY)) {}

  /** Initializes the RCC Oscillators according to the specified parameters
  * in the RCC_OscInitTypeDef structure.
  */
  RCC_OscInitStruct.OscillatorType = RCC_OSCILLATORTYPE_HSI48|RCC_OSCILLATORTYPE_CSI
                              |RCC_OSCILLATORTYPE_HSI;
  RCC_OscInitStruct.HSIState = RCC_HSI_DIV1;
  RCC_OscInitStruct.HSICalibrationValue = RCC_HSICALIBRATION_DEFAULT;
  RCC_OscInitStruct.HSI48State = RCC_HSI48_ON;
  RCC_OscInitStruct.CSIState = RCC_CSI_ON;
  RCC_OscInitStruct.CSICalibrationValue = RCC_CSICALIBRATION_DEFAULT;
  RCC_OscInitStruct.PLL.PLLState = RCC_PLL_ON;
  RCC_OscInitStruct.PLL.PLLSource = RCC_PLLSOURCE_HSI;
  RCC_OscInitStruct.PLL.PLLM = 8;
  RCC_OscInitStruct.PLL.PLLN = 60;
  RCC_OscInitStruct.PLL.PLLP = 2;
  RCC_OscInitStruct.PLL.PLLQ = 4;
  RCC_OscInitStruct.PLL.PLLR = 2;
  RCC_OscInitStruct.PLL.PLLRGE = RCC_PLL1VCIRANGE_3;
  RCC_OscInitStruct.PLL.PLLVCOSEL = RCC_PLL1VCOWIDE;
  RCC_OscInitStruct.PLL.PLLFRACN = 0;
  Debug_SetStage(4U, NULL);
  if (HAL_RCC_OscConfig(&RCC_OscInitStruct) != HAL_OK)
  {
    Error_Handler();
  }

  /** Initializes the CPU, AHB and APB buses clocks
  */
  RCC_ClkInitStruct.ClockType = RCC_CLOCKTYPE_HCLK|RCC_CLOCKTYPE_SYSCLK
                              |RCC_CLOCKTYPE_PCLK1|RCC_CLOCKTYPE_PCLK2
                              |RCC_CLOCKTYPE_D3PCLK1|RCC_CLOCKTYPE_D1PCLK1;
  RCC_ClkInitStruct.SYSCLKSource = RCC_SYSCLKSOURCE_PLLCLK;
  RCC_ClkInitStruct.SYSCLKDivider = RCC_SYSCLK_DIV1;
  RCC_ClkInitStruct.AHBCLKDivider = RCC_HCLK_DIV2;
  RCC_ClkInitStruct.APB3CLKDivider = RCC_APB3_DIV2;
  RCC_ClkInitStruct.APB1CLKDivider = RCC_APB1_DIV2;
  RCC_ClkInitStruct.APB2CLKDivider = RCC_APB2_DIV2;
  RCC_ClkInitStruct.APB4CLKDivider = RCC_APB4_DIV2;

  Debug_SetStage(5U, NULL);
  if (HAL_RCC_ClockConfig(&RCC_ClkInitStruct, FLASH_LATENCY_5) != HAL_OK)
  {
    Error_Handler();
  }
}

void PeriphCommonClock_Config(void)
{
  RCC_PeriphCLKInitTypeDef PeriphClkInitStruct = {0};

  /** Initializes the peripherals clock
  */
  PeriphClkInitStruct.PeriphClockSelection = RCC_PERIPHCLK_CKPER;
  PeriphClkInitStruct.CkperClockSelection = RCC_CLKPSOURCE_HSI;
  if (HAL_RCCEx_PeriphCLKConfig(&PeriphClkInitStruct) != HAL_OK)
  {
    Error_Handler();
  }
}

 /* MPU Configuration */

void MPU_Config(void)
{
  MPU_Region_InitTypeDef MPU_InitStruct = {0};

  /* Disables the MPU */
  HAL_MPU_Disable();

  /** Initializes and configures the Region and the memory to be protected
  */
  MPU_InitStruct.Enable = MPU_REGION_ENABLE;
  MPU_InitStruct.Number = MPU_REGION_NUMBER0;
  MPU_InitStruct.BaseAddress = 0x0;
  MPU_InitStruct.Size = MPU_REGION_SIZE_4GB;
  MPU_InitStruct.SubRegionDisable = 0x87;
  MPU_InitStruct.TypeExtField = MPU_TEX_LEVEL0;
  MPU_InitStruct.AccessPermission = MPU_REGION_NO_ACCESS;
  MPU_InitStruct.DisableExec = MPU_INSTRUCTION_ACCESS_DISABLE;
  MPU_InitStruct.IsShareable = MPU_ACCESS_SHAREABLE;
  MPU_InitStruct.IsCacheable = MPU_ACCESS_NOT_CACHEABLE;
  MPU_InitStruct.IsBufferable = MPU_ACCESS_NOT_BUFFERABLE;

  HAL_MPU_ConfigRegion(&MPU_InitStruct);

  /** Initializes and configures the Region and the memory to be protected
  */
  MPU_InitStruct.Number = MPU_REGION_NUMBER1;
  MPU_InitStruct.BaseAddress = 0x90000000;
  MPU_InitStruct.Size = MPU_REGION_SIZE_256MB;
  MPU_InitStruct.SubRegionDisable = 0x00;
  MPU_InitStruct.AccessPermission = MPU_REGION_FULL_ACCESS;
  MPU_InitStruct.IsShareable = MPU_ACCESS_NOT_SHAREABLE;
  MPU_InitStruct.IsCacheable = MPU_ACCESS_CACHEABLE;

  HAL_MPU_ConfigRegion(&MPU_InitStruct);

  /** Initializes and configures the Region and the memory to be protected
  */
  MPU_InitStruct.Number = MPU_REGION_NUMBER2;
  MPU_InitStruct.BaseAddress = 0xC0000000;
  MPU_InitStruct.Size = MPU_REGION_SIZE_32MB;
  MPU_InitStruct.SubRegionDisable = 0x0;

  HAL_MPU_ConfigRegion(&MPU_InitStruct);

  /** Initializes and configures the Region and the memory to be protected
  */
  MPU_InitStruct.Number = MPU_REGION_NUMBER3;
  MPU_InitStruct.Size = MPU_REGION_SIZE_2MB;
  MPU_InitStruct.IsShareable = MPU_ACCESS_SHAREABLE;
  MPU_InitStruct.IsCacheable = MPU_ACCESS_NOT_CACHEABLE;

  HAL_MPU_ConfigRegion(&MPU_InitStruct);
  /* Enables the MPU */
  HAL_MPU_Enable(MPU_PRIVILEGED_DEFAULT);

}

void Error_Handler(void)
{
  /* USER CODE BEGIN Error_Handler_Debug */
  /* User can add his own implementation to report the HAL error return state */
  GPIO_InitTypeDef GPIO_InitStruct = {0};
  char errMsg[48];
  uint8_t blinkCount = (g_ltdc_stage == 0U) ? 9U : g_ltdc_stage;

  (void)snprintf(errMsg, sizeof(errMsg), "[ERR] Error_Handler stage=%u\r\n", g_ltdc_stage);
  Debug_LogUart5(errMsg);

  __HAL_RCC_GPIOA_CLK_ENABLE();
  __HAL_RCC_GPIOC_CLK_ENABLE();
  __HAL_RCC_GPIOI_CLK_ENABLE();
  GPIO_InitStruct.Pin = LED1_Pin;
  GPIO_InitStruct.Mode = GPIO_MODE_OUTPUT_PP;
  GPIO_InitStruct.Pull = GPIO_NOPULL;
  GPIO_InitStruct.Speed = GPIO_SPEED_FREQ_LOW;
  HAL_GPIO_Init(LED1_GPIO_Port, &GPIO_InitStruct);

  GPIO_InitStruct.Pin = LED2_Pin;
  GPIO_InitStruct.Mode = GPIO_MODE_OUTPUT_PP;
  GPIO_InitStruct.Pull = GPIO_NOPULL;
  GPIO_InitStruct.Speed = GPIO_SPEED_FREQ_LOW;
  HAL_GPIO_Init(LED2_GPIO_Port, &GPIO_InitStruct);

  GPIO_InitStruct.Pin = LED3_Pin;
  GPIO_InitStruct.Mode = GPIO_MODE_OUTPUT_PP;
  GPIO_InitStruct.Pull = GPIO_NOPULL;
  GPIO_InitStruct.Speed = GPIO_SPEED_FREQ_LOW;
  HAL_GPIO_Init(LED3_GPIO_Port, &GPIO_InitStruct);

  __disable_irq();
  while (1)
  {
    HAL_GPIO_WritePin(LED1_GPIO_Port, LED1_Pin, GPIO_PIN_SET);
    HAL_GPIO_WritePin(LED3_GPIO_Port, LED3_Pin, GPIO_PIN_SET);

    for (uint8_t i = 0U; i < blinkCount; i++)
    {
      HAL_GPIO_WritePin(LED2_GPIO_Port, LED2_Pin, GPIO_PIN_SET);
      Debug_SpinDelay(40000000U);
      HAL_GPIO_WritePin(LED2_GPIO_Port, LED2_Pin, GPIO_PIN_RESET);
      Debug_SpinDelay(40000000U);
    }

    HAL_GPIO_WritePin(LED2_GPIO_Port, LED2_Pin, GPIO_PIN_RESET);
    HAL_GPIO_WritePin(LED3_GPIO_Port, LED3_Pin, GPIO_PIN_RESET);
    Debug_SpinDelay(100000000U);
  }
  /* USER CODE END Error_Handler_Debug */
}

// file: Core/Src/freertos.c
/* USER CODE BEGIN Header */
/**
  ******************************************************************************
  * File Name          : freertos.c
  * Description        : Code for freertos applications
  ******************************************************************************
  * @attention
  *
  * Copyright (c) 2026 STMicroelectronics.
  * All rights reserved.
  *
  * This software is licensed under terms that can be found in the LICENSE file
  * in the root directory of this software component.
  * If no LICENSE file comes with this software, it is provided AS-IS.
  *
  ******************************************************************************
  */
/* USER CODE END Header */

#include "FreeRTOS.h"
#include "task.h"
#include "main.h"
#include "cmsis_os.h"

/* USER CODE BEGIN Includes */
#include "fdcan.h"
#include "fatfs.h"
#include "sdmmc.h"
#include "app_config.h"
#include "display_telemetry.h"
#include "display_telemetry_can_config.h"
#include "memorymap.h"
#include "ui_buttons.h"
#include <stdio.h>
#include <string.h>

/* USER CODE END Includes */

/* USER CODE BEGIN PTD */
typedef struct
{
  FDCAN_RxHeaderTypeDef header;
  uint8_t data[8];
  uint8_t length;
  uint32_t tick;
} CanRxFrame;

typedef struct
{
  DisplayTelemetry snapshot;
  uint32_t sequence;
  uint32_t tick;
  uint32_t sourceCanId;
  uint8_t closeRequest;
  uint8_t configSaveRequest;
} TelemetryFanoutPacket;

typedef enum
{
  CONFIG_SOURCE_CAN = 0U,
  CONFIG_SOURCE_LOCAL = 1U
} ConfigSource;

typedef struct
{
  uint8_t source;
  uint8_t key;
  uint16_t value;
  uint32_t originId;
  uint32_t tick;
} ConfigMessage;

typedef struct
{
  FDCAN_TxHeaderTypeDef header;
  uint8_t data[8];
  uint8_t length;
} CanTxMessage;

typedef struct
{
  uint8_t sdLoggingEnabled;
  uint16_t nextLogSession;
} LocalConfigState;

/* USER CODE END PTD */

/* USER CODE BEGIN PD */
#define CAN_RX_QUEUE_LENGTH             32U
#define CAN_TX_QUEUE_LENGTH             16U
#define SD_LOG_QUEUE_LENGTH             16U
#define SD_LOG_MIN_PERIOD_MS            200U
#define CAN_CONFIG_RX_ID                0x120U
#define CAN_CONFIG_TX_ID                0x121U
#define CONFIG_FILE_PATH                "0:/CONFIG.CSV"
/* USER CODE END PD */

/* USER CODE BEGIN Variables */
static volatile DisplayTelemetry g_displayTelemetry = {0};
static volatile uint32_t g_displayTelemetryWriteSequence = 0U;
static volatile uint32_t g_displayTelemetrySnapshotSequence = 0U;
static volatile uint8_t g_displayTelemetryValid = 0U;
static volatile uint32_t g_displayTelemetryPendingMask = 0U;
static uint8_t g_uiButtonsInitialized = 0U;
static volatile uint32_t g_canRxIsrCount = 0U;
static volatile uint32_t g_canRxDroppedFrames = 0U;
static volatile uint8_t g_telemetryTaskEntered = 0U;
static volatile uint8_t g_displayCanReady = 0U;
static volatile uint32_t g_sdLogDroppedFrames = 0U;
static volatile uint32_t g_sdLogQueuedFrames = 0U;
static volatile uint8_t g_sdLogRecordingActive = 0U;
static volatile uint8_t g_sdLogCreateRequested = 0U;
static volatile uint32_t g_canTxDroppedFrames = 0U;
static volatile LocalConfigState g_localConfig = {1U, 0U};
static volatile VehicleConfigParams g_vehicleConfig = {{0U, 0U, 0U, 0U, 0U}};
static uint8_t g_sdFatFsMounted = 0U;
static uint8_t g_configLoadDone = 0U;
static char g_sdLogFilePath[18] = "";
static char g_sdLogSessionId[13] = "NOLOG";
extern uint8_t sdmmc1_init_ok;
static osMessageQueueId_t canRxQueueHandle;
static osMessageQueueId_t canTxQueueHandle;
static osMessageQueueId_t sdLogQueueHandle;
/* USER CODE END Variables */

uint32_t DisplayDiag_GetCanRxIsrCount(void)
{
  return g_canRxIsrCount;
}

uint32_t DisplayDiag_GetCanRxDroppedFrames(void)
{
  return g_canRxDroppedFrames;
}

uint8_t DisplayDiag_GetTelemetryTaskEntered(void)
{
  return g_telemetryTaskEntered;
}

uint8_t DisplayDiag_GetDisplayCanReady(void)
{
  return g_displayCanReady;
}
/* Definitions for defaultTask */
osThreadId_t defaultTaskHandle;
const osThreadAttr_t defaultTask_attributes = {
  .name = "defaultTask",
  .stack_size = 4096 * 4,
  .priority = (osPriority_t) osPriorityNormal,
};
/* Definitions for telemetryTask */
osThreadId_t telemetryTaskHandle;
const osThreadAttr_t telemetryTask_attributes = {
  .name = "telemetryTask",
  .stack_size = 4096 * 4,
  .priority = (osPriority_t) osPriorityAboveNormal,
};
/* Definitions for canTxTask */
osThreadId_t canTxTaskHandle;
const osThreadAttr_t canTxTask_attributes = {
  .name = "canTxTask",
  .stack_size = 4096 * 2,
  .priority = (osPriority_t) osPriorityBelowNormal,
};
/* Definitions for TouchGFXTask */
osThreadId_t TouchGFXTaskHandle;
const osThreadAttr_t TouchGFXTask_attributes = {
  .name = "TouchGFXTask",
  .stack_size = 4096 * 4,
  .priority = (osPriority_t) osPriorityNormal,
};
/* Definitions for sdTask */
osThreadId_t sdTaskHandle;
const osThreadAttr_t sdTask_attributes = {
  .name = "sdTask",
  .stack_size = 4096 * 4,
  .priority = (osPriority_t) osPriorityNormal,
};
/* USER CODE BEGIN FunctionPrototypes */
static uint16_t DisplayTelemetry_ReadU16Le(const uint8_t *data);
static uint16_t DisplayTelemetry_ReadU16Be(const uint8_t *data);
static int16_t DisplayTelemetry_ReadS16Le(const uint8_t *data);
static int16_t DisplayTelemetry_ReadS16Be(const uint8_t *data);
static uint32_t DisplayTelemetry_ReadU32Le(const uint8_t *data);
static int32_t DisplayTelemetry_ReadS32Le(const uint8_t *data);
static uint8_t DisplayTelemetry_ApplySignalConfig(volatile DisplayTelemetry *telemetry, const DisplayTelemetrySignalConfig *signalConfig, const uint8_t *data, uint32_t length);
static uint8_t DisplayTelemetry_ProcessCanFrame(const DisplayTelemetryCanMessageConfig *messageConfig, const uint8_t *data, uint32_t length, uint32_t sourceCanId);
static void DisplayTelemetry_ConfigCanPort(FDCAN_HandleTypeDef *hfdcan);
static void SD_LogFatFsResult(const char *prefix, FRESULT result);
static void SD_TaskInit(void);
static void SD_TaskConsumePacket(const TelemetryFanoutPacket *packet);
static void SD_QueueCloseRequest(void);
static void SD_QueueConfigSaveRequest(void);
static uint8_t SD_EnsureMounted(void);
static void Config_LoadFromSd(void);
static uint8_t Config_ParseBytes(const uint8_t *data,
                                 UINT length,
                                 unsigned int *sdEnabled,
                                 unsigned int *alert0,
                                 unsigned int *alert1,
                                 unsigned int *alert2,
                                 unsigned int *alert3,
                                 unsigned int *alert4,
                                 unsigned int *nextLogSession);
static uint8_t Config_SaveToSd(void);
static FRESULT SD_OpenNextTelemetryLog(FIL *file);
static uint32_t DisplayTelemetry_DecodePayloadLength(uint32_t dlc);
static void Telemetry_FanoutSnapshot(uint32_t sourceCanId);
static void DisplayTelemetry_ProcessRxFrame(const CanRxFrame *frame);
static uint8_t DisplayConfig_ParseCanFrame(const CanRxFrame *frame, ConfigMessage *message);
static uint8_t LocalConfig_Apply(const ConfigMessage *message);
static uint8_t VehicleConfig_Apply(const ConfigMessage *message);
static uint8_t Config_ApplyMessage(const ConfigMessage *message);
static void Config_SendCanAck(const ConfigMessage *message, uint8_t applied);
static void CanTx_QueueMessage(const CanTxMessage *message);
static void CanTx_FillConfigHeader(FDCAN_TxHeaderTypeDef *header, uint32_t canId, uint32_t dlc);
static uint8_t VehicleConfig_IsAlertIndexValid(uint8_t index);
static uint8_t VehicleConfig_AlertIndexToKey(uint8_t index);
static uint8_t VehicleConfig_KeyToAlertIndex(uint8_t key, uint8_t *index);
static uint16_t VehicleConfig_ClampAlertValue(uint8_t index, uint16_t value);
/* USER CODE END FunctionPrototypes */

void StartDefaultTask(void *argument);
void StartTelemetryTask(void *argument);
void StartCanTxTask(void *argument);
void StartSdTask(void *argument);
extern void TouchGFX_Task(void *argument);

void MX_FREERTOS_Init(void); /* (MISRA C 2004 rule 8.1) */

void MX_FREERTOS_Init(void) {

  /* USER CODE BEGIN RTOS_QUEUES */
  canRxQueueHandle = osMessageQueueNew(CAN_RX_QUEUE_LENGTH, sizeof(CanRxFrame), NULL);
  canTxQueueHandle = osMessageQueueNew(CAN_TX_QUEUE_LENGTH, sizeof(CanTxMessage), NULL);
  sdLogQueueHandle = osMessageQueueNew(SD_LOG_QUEUE_LENGTH, sizeof(TelemetryFanoutPacket), NULL);
  /* USER CODE END RTOS_QUEUES */

  /* Create the thread(s) */
  /* creation of defaultTask */
  defaultTaskHandle = osThreadNew(StartDefaultTask, NULL, &defaultTask_attributes);

  /* creation of telemetryTask */
  telemetryTaskHandle = osThreadNew(StartTelemetryTask, NULL, &telemetryTask_attributes);

  /* creation of canTxTask */
  canTxTaskHandle = osThreadNew(StartCanTxTask, NULL, &canTxTask_attributes);

  /* creation of TouchGFXTask */
  TouchGFXTaskHandle = osThreadNew(TouchGFX_Task, NULL, &TouchGFXTask_attributes);

  /* creation of sdTask */
  sdTaskHandle = osThreadNew(StartSdTask, NULL, &sdTask_attributes);

  /* USER CODE BEGIN RTOS_THREADS */
  Debug_LogUart5((canRxQueueHandle != NULL) ? "[RTOS] canRxQueue created\r\n" : "[RTOS] canRxQueue create FAIL\r\n");
  Debug_LogUart5((canTxQueueHandle != NULL) ? "[RTOS] canTxQueue created\r\n" : "[RTOS] canTxQueue create FAIL\r\n");
  Debug_LogUart5((sdLogQueueHandle != NULL) ? "[RTOS] sdLogQueue created\r\n" : "[RTOS] sdLogQueue create FAIL\r\n");
  Debug_LogUart5((defaultTaskHandle != NULL) ? "[RTOS] defaultTask created\r\n" : "[RTOS] defaultTask create FAIL\r\n");
  Debug_LogUart5((telemetryTaskHandle != NULL) ? "[RTOS] telemetryTask created\r\n" : "[RTOS] telemetryTask create FAIL\r\n");
  Debug_LogUart5((canTxTaskHandle != NULL) ? "[RTOS] canTxTask created\r\n" : "[RTOS] canTxTask create FAIL\r\n");
  Debug_LogUart5((TouchGFXTaskHandle != NULL) ? "[RTOS] TouchGFXTask created\r\n" : "[RTOS] TouchGFXTask create FAIL\r\n");
  Debug_LogUart5((sdTaskHandle != NULL) ? "[RTOS] sdTask created\r\n" : "[RTOS] sdTask create FAIL\r\n");
  /* USER CODE END RTOS_THREADS */

}

void StartDefaultTask(void *argument)
{
  /* USER CODE BEGIN StartDefaultTask */
  uint32_t lastRuntimeLogTick = 0U;

  g_ltdc_stage = 12U;
  HAL_GPIO_WritePin(LED1_GPIO_Port, LED1_Pin, GPIO_PIN_SET);
  Debug_LogUart5("[RTOS] defaultTask entered\r\n");
  Debug_LogUart5("[RTOS] scheduler alive\r\n");
  for(;;)
  {
    if (g_uiButtonsInitialized == 0U)
    {
      UIButtons_TaskInit();
      g_uiButtonsInitialized = 1U;
      Debug_LogUart5("[RTOS] ui buttons ready\r\n");
    }
    UIButtons_TaskPoll();
    if ((HAL_GetTick() - lastRuntimeLogTick) >= 1000U)
    {
      lastRuntimeLogTick = HAL_GetTick();
      DisplayDiag_LogRuntime();
    }

    osDelay(5U);
  }
  /* USER CODE END StartDefaultTask */
}

void StartTelemetryTask(void *argument)
{
  /* USER CODE BEGIN StartTelemetryTask */
  CanRxFrame frame;

  (void)argument;
  g_telemetryTaskEntered = 1U;
  Debug_LogUart5("[RTOS] telemetryTask entered\r\n");
  DisplayTelemetry_TaskInit();
  Debug_LogUart5("[RTOS] display telemetry task ready\r\n");

  for (;;)
  {
    if (osMessageQueueGet(canRxQueueHandle, &frame, NULL, 1000U) == osOK)
    {
      DisplayTelemetry_ProcessRxFrame(&frame);
      DisplayTelemetry_TaskStep();
    }
  }
  /* USER CODE END StartTelemetryTask */
}

void StartCanTxTask(void *argument)
{
  /* USER CODE BEGIN StartCanTxTask */
  CanTxMessage message;

  (void)argument;
  Debug_LogUart5("[RTOS] canTxTask entered\r\n");

  for (;;)
  {
    if (osMessageQueueGet(canTxQueueHandle, &message, NULL, osWaitForever) == osOK)
    {
      while (HAL_FDCAN_GetTxFifoFreeLevel(&hfdcan1) == 0U)
      {
        osDelay(1U);
      }

      if (HAL_FDCAN_AddMessageToTxFifoQ(&hfdcan1, &message.header, message.data) != HAL_OK)
      {
        Debug_LogUart5("[CAN] tx enqueue to hw FAIL\r\n");
      }
    }
  }
  /* USER CODE END StartCanTxTask */
}

void StartSdTask(void *argument)
{
  /* USER CODE BEGIN StartSdTask */
  TelemetryFanoutPacket packet;

  (void)argument;
  Debug_LogUart5("[RTOS] sdTask entered\r\n");
  osDelay(2000U);
  SD_TaskInit();

  for (;;)
  {
    if (osMessageQueueGet(sdLogQueueHandle, &packet, NULL, 1000U) == osOK)
    {
      SD_TaskConsumePacket(&packet);
    }
    else if (g_configLoadDone == 0U)
    {
      Config_LoadFromSd();
    }
  }
  /* USER CODE END StartSdTask */
}

/* USER CODE BEGIN Application */

static void SD_LogFatFsResult(const char *prefix, FRESULT result)
{
  char buffer[64];

  (void)snprintf(buffer,
                 sizeof(buffer),
                 "[SD] %s -> FR=%lu\r\n",
                 (prefix != NULL) ? prefix : "op",
                 (unsigned long)result);
  Debug_LogUart5(buffer);
}

static void SD_TaskInit(void)
{
  Config_LoadFromSd();
}

static uint8_t SD_EnsureMounted(void)
{
  FRESULT fr;

  if (g_sdFatFsMounted != 0U)
  {
    return 1U;
  }

  fr = f_mount(&SDFatFS, SDPath, 1);
  if (fr != FR_OK)
  {
    sdmmc1_init_ok = 0U;
    SD_LogFatFsResult("mount fail", fr);
    osDelay(1000U);
    return 0U;
  }

  sdmmc1_init_ok = 1U;
  g_sdFatFsMounted = 1U;
  return 1U;
}

static uint8_t Config_ParseBytes(const uint8_t *data,
                                 UINT length,
                                 unsigned int *sdEnabled,
                                 unsigned int *alert0,
                                 unsigned int *alert1,
                                 unsigned int *alert2,
                                 unsigned int *alert3,
                                 unsigned int *alert4,
                                 unsigned int *nextLogSession)
{
  unsigned int values[7];
  unsigned int bestValues[7];
  uint8_t count = 0U;
  uint8_t bestCount = 0U;
  uint8_t lineHasText = 0U;
  UINT i;

  if ((data == NULL) ||
      (sdEnabled == NULL) ||
      (alert0 == NULL) ||
      (alert1 == NULL) ||
      (alert2 == NULL) ||
      (alert3 == NULL) ||
      (alert4 == NULL) ||
      (nextLogSession == NULL))
  {
    return 0U;
  }

  values[6] = *nextLogSession;
  bestValues[6] = *nextLogSession;
  for (i = 0U; i < length; ++i)
  {
    if (((data[i] >= (uint8_t)'A') && (data[i] <= (uint8_t)'Z')) ||
        ((data[i] >= (uint8_t)'a') && (data[i] <= (uint8_t)'z')))
    {
      lineHasText = 1U;
    }
    else if ((count < 7U) && (data[i] >= (uint8_t)'0') && (data[i] <= (uint8_t)'9'))
    {
      unsigned int value = 0U;

      do
      {
        value = (value * 10U) + (unsigned int)(data[i] - (uint8_t)'0');
        ++i;
        while ((i < length) && (data[i] == 0U))
        {
          ++i;
        }
      } while ((i < length) && (data[i] >= (uint8_t)'0') && (data[i] <= (uint8_t)'9'));

      values[count++] = value;
    }

    if ((data[i] == (uint8_t)'\n') || (data[i] == (uint8_t)'\r'))
    {
      if ((lineHasText == 0U) && (count >= 6U))
      {
        for (uint8_t j = 0U; j < 7U; ++j)
        {
          bestValues[j] = values[j];
        }
        bestCount = count;
      }
      values[6] = *nextLogSession;
      count = 0U;
      lineHasText = 0U;
    }
  }

  if ((lineHasText == 0U) && (count >= 6U))
  {
    for (uint8_t j = 0U; j < 7U; ++j)
    {
      bestValues[j] = values[j];
    }
    bestCount = count;
  }

  if (bestCount < 6U)
  {
    return 0U;
  }

  *sdEnabled = bestValues[0];
  *alert0 = bestValues[1];
  *alert1 = bestValues[2];
  *alert2 = bestValues[3];
  *alert3 = bestValues[4];
  *alert4 = bestValues[5];
  *nextLogSession = bestValues[6];
  return 1U;
}

static void Config_LoadFromSd(void)
{
  FIL file;
  uint8_t fileBuffer[256];
  UINT bytesRead = 0U;
  unsigned int sdEnabled;
  unsigned int alert0;
  unsigned int alert1;
  unsigned int alert2;
  unsigned int alert3;
  unsigned int alert4;
  unsigned int nextLogSession = 0U;
  FRESULT fr;

  if (SD_EnsureMounted() == 0U)
  {
    return;
  }

  fr = f_open(&file, CONFIG_FILE_PATH, FA_READ);
  if (fr != FR_OK)
  {
    if (fr == FR_NO_FILE)
    {
      g_configLoadDone = Config_SaveToSd();
    }
    return;
  }

  fr = f_read(&file, fileBuffer, sizeof(fileBuffer), &bytesRead);
  if ((fr == FR_OK) &&
      (Config_ParseBytes(fileBuffer, bytesRead, &sdEnabled, &alert0, &alert1, &alert2, &alert3, &alert4, &nextLogSession) != 0U))
  {
    g_localConfig.sdLoggingEnabled = (sdEnabled != 0U) ? 1U : 0U;
    g_localConfig.nextLogSession = (uint16_t)(nextLogSession % 1000U);
    g_vehicleConfig.alertThresholds[0] = VehicleConfig_ClampAlertValue(0U, (uint16_t)alert0);
    g_vehicleConfig.alertThresholds[1] = VehicleConfig_ClampAlertValue(1U, (uint16_t)alert1);
    g_vehicleConfig.alertThresholds[2] = VehicleConfig_ClampAlertValue(2U, (uint16_t)alert2);
    g_vehicleConfig.alertThresholds[3] = VehicleConfig_ClampAlertValue(3U, (uint16_t)alert3);
    g_vehicleConfig.alertThresholds[4] = VehicleConfig_ClampAlertValue(4U, (uint16_t)alert4);
  }
  else
  {
    (void)f_close(&file);
    return;
  }

  (void)f_close(&file);
  g_configLoadDone = 1U;
}

static uint8_t Config_SaveToSd(void)
{
  FIL file;
  UINT written = 0U;
  char buffer[160];
  UINT length;
  FRESULT fr;

  if (SD_EnsureMounted() == 0U)
  {
    return 0U;
  }

  length = (UINT)snprintf(buffer,
                          sizeof(buffer),
                          "sd_logging_enabled,alert_motor_temp,alert_inverter_temp,alert_accu_temp,alert_soc,alert_accu_min_voltage,next_log_session\r\n"
                          "%u,%u,%u,%u,%u,%u,%u\r\n",
                          (unsigned)g_localConfig.sdLoggingEnabled,
                          (unsigned)g_vehicleConfig.alertThresholds[0],
                          (unsigned)g_vehicleConfig.alertThresholds[1],
                          (unsigned)g_vehicleConfig.alertThresholds[2],
                          (unsigned)g_vehicleConfig.alertThresholds[3],
                          (unsigned)g_vehicleConfig.alertThresholds[4],
                          (unsigned)g_localConfig.nextLogSession);
  if ((length == 0U) || (length >= sizeof(buffer)))
  {
    return 0U;
  }

  fr = f_open(&file, CONFIG_FILE_PATH, FA_CREATE_ALWAYS | FA_WRITE);
  if (fr != FR_OK)
  {
    SD_LogFatFsResult("open config fail", fr);
    return 0U;
  }

  fr = f_write(&file, buffer, length, &written);
  if ((fr != FR_OK) || (written != length))
  {
    SD_LogFatFsResult("write config fail", fr);
    (void)f_close(&file);
    return 0U;
  }

  fr = f_close(&file);
  if (fr != FR_OK)
  {
    SD_LogFatFsResult("close config fail", fr);
    return 0U;
  }

  return 1U;
}

static FRESULT SD_OpenNextTelemetryLog(FIL *file)
{
  FRESULT fr;
  uint16_t session;
  uint16_t attempt;
  char sessionId[13];
  char filePath[18];

  if (file == NULL)
  {
    return FR_INVALID_OBJECT;
  }

  session = (uint16_t)(g_localConfig.nextLogSession % 1000U);

  for (attempt = 0U; attempt < 1000U; attempt++)
  {
    (void)snprintf(sessionId,
                   sizeof(sessionId),
                   "TELOG%03u.CSV",
                   (unsigned)session);
    (void)snprintf(filePath,
                   sizeof(filePath),
                   "0:/%s",
                   sessionId);

    fr = f_open(file, filePath, FA_CREATE_NEW | FA_WRITE);
    if (fr == FR_OK)
    {
      (void)snprintf(g_sdLogSessionId, sizeof(g_sdLogSessionId), "%s", sessionId);
      (void)snprintf(g_sdLogFilePath, sizeof(g_sdLogFilePath), "%s", filePath);
      g_localConfig.nextLogSession = (uint16_t)((session + 1U) % 1000U);
      return FR_OK;
    }

    if (fr != FR_EXIST)
    {
      (void)snprintf(g_sdLogSessionId, sizeof(g_sdLogSessionId), "NOLOG");
      g_sdLogFilePath[0] = '\0';
      return fr;
    }

    session = (uint16_t)((session + 1U) % 1000U);
  }

  (void)snprintf(g_sdLogSessionId, sizeof(g_sdLogSessionId), "NOLOG");
  return FR_DENIED;
}

static void SD_TaskConsumePacket(const TelemetryFanoutPacket *packet)
{
  static uint8_t fileReady = 0U;
  FRESULT fr;
  UINT bytesProcessed = 0U;
  char lineBuffer[512];

  if (packet == NULL)
  {
    return;
  }

  if ((g_configLoadDone == 0U) && (packet->configSaveRequest == 0U))
  {
    Config_LoadFromSd();
  }

  if (packet->configSaveRequest != 0U)
  {
    Config_SaveToSd();
    return;
  }

  if (packet->closeRequest != 0U)
  {
    fileReady = 0U;
    g_sdLogRecordingActive = 0U;
    return;
  }

  if (g_localConfig.sdLoggingEnabled == 0U)
  {
    g_sdLogRecordingActive = 0U;
    g_sdLogCreateRequested = 0U;
    return;
  }

  if ((fileReady == 0U) &&
      (g_sdLogCreateRequested == 0U) &&
      (g_sdLogFilePath[0] == '\0'))
  {
    g_sdLogRecordingActive = 0U;
    return;
  }

  if (g_sdFatFsMounted == 0U)
  {
    if (SD_EnsureMounted() == 0U)
    {
      g_sdLogRecordingActive = 0U;
      return;
    }
  }

  if (fileReady == 0U)
  {
    if (g_sdLogCreateRequested == 0U)
    {
      fileReady = 1U;
      g_sdLogRecordingActive = 1U;
    }
  }

  if (fileReady == 0U)
  {
    FIL logFile;
    fr = SD_OpenNextTelemetryLog(&logFile);
    if (fr != FR_OK)
    {
      g_sdLogRecordingActive = 0U;
      SD_LogFatFsResult("open log fail", fr);
      g_sdFatFsMounted = 0U;
      return;
    }

    static const char header[] = "#TELOG\r\n";
    UINT headerWritten = 0U;

    fr = f_write(&logFile, header, sizeof(header) - 1U, &headerWritten);
    if ((fr != FR_OK) || (headerWritten != (sizeof(header) - 1U)))
    {
      g_sdLogRecordingActive = 0U;
      SD_LogFatFsResult("header write fail", fr);
      (void)f_close(&logFile);
      (void)snprintf(g_sdLogSessionId, sizeof(g_sdLogSessionId), "NOLOG");
      g_sdLogFilePath[0] = '\0';
      g_sdFatFsMounted = 0U;
      return;
    }

    fr = f_close(&logFile);
    if (fr != FR_OK)
    {
      g_sdLogRecordingActive = 0U;
      SD_LogFatFsResult("header close fail", fr);
      fileReady = 0U;
      (void)snprintf(g_sdLogSessionId, sizeof(g_sdLogSessionId), "NOLOG");
      g_sdLogFilePath[0] = '\0';
      g_sdFatFsMounted = 0U;
      return;
    }

    fileReady = 1U;
    g_sdLogCreateRequested = 0U;
    g_configLoadDone = Config_SaveToSd();
    g_sdLogRecordingActive = (g_localConfig.sdLoggingEnabled != 0U) ? 1U : 0U;
  }

  bytesProcessed = (UINT)snprintf(lineBuffer,
                                  sizeof(lineBuffer),
                                  "%lu,%u,"
                                  "%u,%u,%u,%u,%u,%u,%u,%u,"
                                  "%u,%u,%u,%u,"
                                  "%u,%u,%u,%u,%u,"
                                  "%u,%u,%u,%u,%u,"
                                  "%d,%d,%d,"
                                  "%d,%d,%d,%d,%d,"
                                  "%u,%u,%u,%u,"
                                  "%d,%d,%d,%ld,%ld,%ld,"
                                  "%u,%u,%ld,%u,%u,%u,%ld,%ld\r\n",
                                  (unsigned long)packet->snapshot.tick_ms,
                                  (unsigned)packet->snapshot.sequence,
                                  (unsigned)packet->snapshot.ecu_fsm_state,
                                  (unsigned)packet->snapshot.ecu_boton_arranque,
                                  (unsigned)packet->snapshot.ecu_s1_aceleracion,
                                  (unsigned)packet->snapshot.ecu_s2_aceleracion,
                                  (unsigned)packet->snapshot.ecu_s_freno,
                                  (unsigned)packet->snapshot.ecu_torque_total,
                                  (unsigned)packet->snapshot.ecu_flag_ev_2_3,
                                  (unsigned)packet->snapshot.ecu_flag_t11_8_9,
                                  (unsigned)packet->snapshot.ams_ok_precarga,
                                  (unsigned)packet->snapshot.ams_state,
                                  (unsigned)packet->snapshot.ams_v_celda_min,
                                  (unsigned)packet->snapshot.ams_soc,
                                  (unsigned)packet->snapshot.ams_vmin_modulo[0],
                                  (unsigned)packet->snapshot.ams_vmin_modulo[1],
                                  (unsigned)packet->snapshot.ams_vmin_modulo[2],
                                  (unsigned)packet->snapshot.ams_vmin_modulo[3],
                                  (unsigned)packet->snapshot.ams_vmin_modulo[4],
                                  (unsigned)packet->snapshot.ams_vmax_modulo[0],
                                  (unsigned)packet->snapshot.ams_vmax_modulo[1],
                                  (unsigned)packet->snapshot.ams_vmax_modulo[2],
                                  (unsigned)packet->snapshot.ams_vmax_modulo[3],
                                  (unsigned)packet->snapshot.ams_vmax_modulo[4],
                                  (int)packet->snapshot.ams_corriente_accu,
                                  (int)packet->snapshot.ams_corriente_dcdc,
                                  (int)packet->snapshot.ams_temp_dcdc,
                                  (int)packet->snapshot.ams_temp_max_modulo[0],
                                  (int)packet->snapshot.ams_temp_max_modulo[1],
                                  (int)packet->snapshot.ams_temp_max_modulo[2],
                                  (int)packet->snapshot.ams_temp_max_modulo[3],
                                  (int)packet->snapshot.ams_temp_max_modulo[4],
                                  (unsigned)packet->snapshot.inverter_inv_state,
                                  (unsigned)packet->snapshot.inverter_inv_vdc_ready,
                                  (unsigned)packet->snapshot.inverter_inv_error,
                                  (unsigned)packet->snapshot.inverter_inv_dc_bus_voltage,
                                  (int)packet->snapshot.inverter_inv_motor_temp,
                                  (int)packet->snapshot.inverter_inv_igbt_temp,
                                  (int)packet->snapshot.inverter_inv_air_temp,
                                  (long)packet->snapshot.inverter_inv_rpm,
                                  (long)packet->snapshot.inverter_inv_speed_actual,
                                  (long)packet->snapshot.inverter_inv_current_actual,
                                  (unsigned)packet->snapshot.gps_speed,
                                  (unsigned)packet->snapshot.gps_course_deg,
                                  (long)packet->snapshot.gps_altitude,
                                  (unsigned)packet->snapshot.gps_fix_type,
                                  (unsigned)packet->snapshot.gps_sat_count,
                                  (unsigned)packet->snapshot.gps_hdop,
                                  (long)packet->snapshot.gps_latitude,
                                  (long)packet->snapshot.gps_longitude);

  if ((bytesProcessed == 0U) || (bytesProcessed >= sizeof(lineBuffer)))
  {
    Debug_LogUart5("[SD] telemetry row truncated\r\n");
    return;
  }

  {
    FIL logFile;
    UINT lineWritten = 0U;
    fr = f_open(&logFile, g_sdLogFilePath, FA_OPEN_APPEND | FA_WRITE);
    if (fr != FR_OK)
    {
      g_sdLogRecordingActive = 0U;
      SD_LogFatFsResult("open log append fail", fr);
      fileReady = 0U;
      g_sdFatFsMounted = 0U;
      return;
    }

    fr = f_write(&logFile, lineBuffer, bytesProcessed, &lineWritten);
    if ((fr != FR_OK) || (lineWritten != bytesProcessed))
    {
      g_sdLogRecordingActive = 0U;
      SD_LogFatFsResult("log write fail", fr);
      (void)f_close(&logFile);
      fileReady = 0U;
      g_sdFatFsMounted = 0U;
      return;
    }

    fr = f_close(&logFile);
    if (fr != FR_OK)
    {
      g_sdLogRecordingActive = 0U;
      SD_LogFatFsResult("log close fail", fr);
      fileReady = 0U;
      g_sdFatFsMounted = 0U;
      return;
    }
  }

  g_sdLogRecordingActive = (g_localConfig.sdLoggingEnabled != 0U) ? 1U : 0U;
}

static uint16_t DisplayTelemetry_ReadU16Le(const uint8_t *data)
{
  return (uint16_t)((uint16_t)data[0] | ((uint16_t)data[1] << 8));
}

static uint16_t DisplayTelemetry_ReadU16Be(const uint8_t *data)
{
  return (uint16_t)(((uint16_t)data[0] << 8) | (uint16_t)data[1]);
}

static int16_t DisplayTelemetry_ReadS16Le(const uint8_t *data)
{
  return (int16_t)DisplayTelemetry_ReadU16Le(data);
}

static int16_t DisplayTelemetry_ReadS16Be(const uint8_t *data)
{
  return (int16_t)DisplayTelemetry_ReadU16Be(data);
}

static uint32_t DisplayTelemetry_ReadU32Le(const uint8_t *data)
{
  return ((uint32_t)data[0]) |
         ((uint32_t)data[1] << 8) |
         ((uint32_t)data[2] << 16) |
         ((uint32_t)data[3] << 24);
}

static int32_t DisplayTelemetry_ReadS32Le(const uint8_t *data)
{
  return (int32_t)DisplayTelemetry_ReadU32Le(data);
}

static uint8_t DisplayTelemetry_ApplySignalConfig(volatile DisplayTelemetry *telemetry, const DisplayTelemetrySignalConfig *signalConfig, const uint8_t *data, uint32_t length)
{
  volatile uint8_t *telemetryBytes = NULL;
  volatile void *destination = NULL;
  uint32_t rawUnsignedValue = 0U;
  int32_t rawSignedValue = 0;
  uint8_t isSignedValue = 0U;

  if ((telemetry == NULL) || (signalConfig == NULL) || (data == NULL))
  {
    return 0U;
  }

  if ((length < signalConfig->minPayloadLength) || (length > signalConfig->maxPayloadLength))
  {
    return 0U;
  }

  if ((signalConfig->telemetryOffset + signalConfig->telemetrySize) > sizeof(DisplayTelemetry))
  {
    return 0U;
  }

  telemetryBytes = (volatile uint8_t *)telemetry;
  destination = (volatile void *)(telemetryBytes + signalConfig->telemetryOffset);

  switch (signalConfig->encoding)
  {
    case DISPLAY_TELEMETRY_SIGNAL_ENCODING_U8:
      if ((signalConfig->payloadOffset + 1U) > length)
      {
        return 0U;
      }
      rawUnsignedValue = data[signalConfig->payloadOffset];
      break;

    case DISPLAY_TELEMETRY_SIGNAL_ENCODING_BIT:
      if ((signalConfig->payloadOffset + 1U) > length)
      {
        return 0U;
      }
      rawUnsignedValue = ((data[signalConfig->payloadOffset] & signalConfig->bitMask) != 0U) ? 1U : 0U;
      break;

    case DISPLAY_TELEMETRY_SIGNAL_ENCODING_U16_LE:
      if ((signalConfig->payloadOffset + 2U) > length)
      {
        return 0U;
      }
      rawUnsignedValue = (uint32_t)DisplayTelemetry_ReadU16Le(&data[signalConfig->payloadOffset]);
      break;

    case DISPLAY_TELEMETRY_SIGNAL_ENCODING_U16_BE:
      if ((signalConfig->payloadOffset + 2U) > length)
      {
        return 0U;
      }
      rawUnsignedValue = (uint32_t)DisplayTelemetry_ReadU16Be(&data[signalConfig->payloadOffset]);
      break;

    case DISPLAY_TELEMETRY_SIGNAL_ENCODING_S16_LE:
      if ((signalConfig->payloadOffset + 2U) > length)
      {
        return 0U;
      }
      rawSignedValue = (int32_t)DisplayTelemetry_ReadS16Le(&data[signalConfig->payloadOffset]);
      isSignedValue = 1U;
      break;

    case DISPLAY_TELEMETRY_SIGNAL_ENCODING_S16_BE:
      if ((signalConfig->payloadOffset + 2U) > length)
      {
        return 0U;
      }
      rawSignedValue = (int32_t)DisplayTelemetry_ReadS16Be(&data[signalConfig->payloadOffset]);
      isSignedValue = 1U;
      break;

    case DISPLAY_TELEMETRY_SIGNAL_ENCODING_U32_LE:
      if ((signalConfig->payloadOffset + 4U) > length)
      {
        return 0U;
      }
      rawUnsignedValue = DisplayTelemetry_ReadU32Le(&data[signalConfig->payloadOffset]);
      break;

    case DISPLAY_TELEMETRY_SIGNAL_ENCODING_S32_LE:
      if ((signalConfig->payloadOffset + 4U) > length)
      {
        return 0U;
      }
      rawSignedValue = DisplayTelemetry_ReadS32Le(&data[signalConfig->payloadOffset]);
      isSignedValue = 1U;
      break;

    default:
      return 0U;
  }

  if (isSignedValue != 0U)
  {
    switch (signalConfig->telemetrySize)
    {
      case 1U:
        *(volatile int8_t *)destination = (int8_t)rawSignedValue;
        break;

      case 2U:
        *(volatile int16_t *)destination = (int16_t)rawSignedValue;
        break;

      case 4U:
        *(volatile int32_t *)destination = rawSignedValue;
        break;

      default:
        return 0U;
    }
  }
  else
  {
    switch (signalConfig->telemetrySize)
    {
      case 1U:
        *(volatile uint8_t *)destination = (uint8_t)rawUnsignedValue;
        break;

      case 2U:
        *(volatile uint16_t *)destination = (uint16_t)rawUnsignedValue;
        break;

      case 4U:
        *(volatile uint32_t *)destination = rawUnsignedValue;
        break;

      default:
        return 0U;
    }
  }

  return 1U;
}

void DisplayTelemetry_Reset(void)
{
  (void)memset((void *)&g_displayTelemetry, 0, sizeof(g_displayTelemetry));
  g_displayTelemetryWriteSequence = 0U;
  g_displayTelemetrySnapshotSequence = 0U;
  g_displayTelemetryValid = 0U;
  g_displayTelemetryPendingMask = 0U;
}

void DisplayTelemetry_TaskInit(void)
{
  g_displayCanReady = 0U;
  DisplayTelemetry_ConfigCanPort(&hfdcan1);
  DisplayTelemetry_ConfigCanPort(&hfdcan2);
  DisplayTelemetry_Reset();
  g_displayCanReady = 1U;
  Debug_LogUart5("[CAN] FDCAN1+2 display telemetry ready\r\n");
}

static void DisplayTelemetry_ConfigCanPort(FDCAN_HandleTypeDef *hfdcan)
{
  FDCAN_FilterTypeDef filter = {0};
  FDCAN_FilterTypeDef configFilter = {0};
  uint32_t lowestAcceptedId = DisplayTelemetryCanConfig_GetMinId();
  uint32_t highestAcceptedId = DisplayTelemetryCanConfig_GetMaxId();

  if (hfdcan == NULL)
  {
    Error_Handler();
  }

  configFilter.IdType = FDCAN_STANDARD_ID;
  configFilter.FilterIndex = 0;
  configFilter.FilterType = FDCAN_FILTER_MASK;
  configFilter.FilterConfig = FDCAN_FILTER_TO_RXFIFO0;
  configFilter.FilterID1 = CAN_CONFIG_RX_ID;
  configFilter.FilterID2 = 0x7FFU;

  if (HAL_FDCAN_ConfigFilter(hfdcan, &configFilter) != HAL_OK)
  {
    Error_Handler();
  }

  filter.IdType = FDCAN_STANDARD_ID;
  filter.FilterIndex = 1;
  filter.FilterType = FDCAN_FILTER_RANGE;
  filter.FilterConfig = FDCAN_FILTER_TO_RXFIFO0;
  filter.FilterID1 = lowestAcceptedId;
  filter.FilterID2 = highestAcceptedId;

  if (HAL_FDCAN_ConfigFilter(hfdcan, &filter) != HAL_OK)
  {
    Error_Handler();
  }

  if (HAL_FDCAN_Start(hfdcan) != HAL_OK)
  {
    Error_Handler();
  }

  if (HAL_FDCAN_ActivateNotification(hfdcan, FDCAN_IT_RX_FIFO0_NEW_MESSAGE, 0U) != HAL_OK)
  {
    Error_Handler();
  }
}

void DisplayTelemetry_TaskStep(void)
{
  CanRxFrame frame;

  while (osMessageQueueGet(canRxQueueHandle, &frame, NULL, 0U) == osOK)
  {
    DisplayTelemetry_ProcessRxFrame(&frame);
  }
}

static uint8_t DisplayTelemetry_ProcessCanFrame(const DisplayTelemetryCanMessageConfig *messageConfig, const uint8_t *data, uint32_t length, uint32_t sourceCanId)
{
  uint32_t appliedSignalCount = 0U;
  uint32_t receivedMaskBit = 0U;

  if ((messageConfig == NULL) || (data == NULL) || (length == 0U))
  {
    return 0U;
  }

  g_displayTelemetryWriteSequence++;
  __DMB();

  for (uint32_t signalIndex = 0U; signalIndex < messageConfig->signalCount; signalIndex++)
  {
    appliedSignalCount += DisplayTelemetry_ApplySignalConfig(&g_displayTelemetry,
                                                             &messageConfig->signals[signalIndex],
                                                             data,
                                                             length);
  }

  if (appliedSignalCount == 0U)
  {
    __DMB();
    g_displayTelemetryWriteSequence++;
    return 0U;
  }

  receivedMaskBit = messageConfig->snapshotMask;
  g_displayTelemetryPendingMask |= receivedMaskBit;
  g_displayTelemetryValid = 1U;
  g_displayTelemetrySnapshotSequence++;

  if (g_displayTelemetryPendingMask == DisplayTelemetryCanConfig_GetSnapshotMaskAll())
  {
    g_displayTelemetryPendingMask = 0U;
  }

  __DMB();
  g_displayTelemetryWriteSequence++;
  Telemetry_FanoutSnapshot(sourceCanId);

  return 1U;
}

uint8_t DisplayTelemetry_GetSnapshot(DisplayTelemetry *snapshot, uint32_t *sequence)
{
  DisplayTelemetry localSnapshot;
  uint32_t writeSequenceStart = 0U;
  uint32_t writeSequenceEnd = 0U;
  uint32_t snapshotSequence = 0U;

  if ((snapshot == NULL) || (g_displayTelemetryValid == 0U))
  {
    return 0U;
  }

  do
  {
    writeSequenceStart = g_displayTelemetryWriteSequence;
    if ((writeSequenceStart & 1U) != 0U)
    {
      continue;
    }

    __DMB();
    snapshotSequence = g_displayTelemetrySnapshotSequence;
    localSnapshot = g_displayTelemetry;
    __DMB();
    writeSequenceEnd = g_displayTelemetryWriteSequence;
  } while ((writeSequenceStart != writeSequenceEnd) || ((writeSequenceEnd & 1U) != 0U));

  if (snapshotSequence == 0U)
  {
    return 0U;
  }

  *snapshot = localSnapshot;

  if (sequence != NULL)
  {
    *sequence = snapshotSequence;
  }

  return 1U;
}

static uint32_t DisplayTelemetry_DecodePayloadLength(uint32_t dlc)
{
  switch (dlc)
  {
    case FDCAN_DLC_BYTES_0:
      return 0U;
    case FDCAN_DLC_BYTES_1:
      return 1U;
    case FDCAN_DLC_BYTES_2:
      return 2U;
    case FDCAN_DLC_BYTES_3:
      return 3U;
    case FDCAN_DLC_BYTES_4:
      return 4U;
    case FDCAN_DLC_BYTES_5:
      return 5U;
    case FDCAN_DLC_BYTES_6:
      return 6U;
    case FDCAN_DLC_BYTES_7:
      return 7U;
    case FDCAN_DLC_BYTES_8:
      return 8U;
    default:
      return 0U;
  }
}

static void Telemetry_FanoutSnapshot(uint32_t sourceCanId)
{
  static uint32_t lastSdLogTick = 0U;
  TelemetryFanoutPacket packet = {0};
  uint32_t now = HAL_GetTick();

  if (DisplayTelemetry_GetSnapshot(&packet.snapshot, &packet.sequence) == 0U)
  {
    return;
  }

  packet.tick = now;
  packet.sourceCanId = sourceCanId;
  packet.closeRequest = 0U;

  if ((sdLogQueueHandle != NULL) &&
      (g_localConfig.sdLoggingEnabled != 0U) &&
      ((g_sdLogRecordingActive != 0U) ||
       (g_sdLogCreateRequested != 0U) ||
       (g_sdLogFilePath[0] != '\0')))
  {
    if (((now - lastSdLogTick) < SD_LOG_MIN_PERIOD_MS) ||
        (osMessageQueueGetCount(sdLogQueueHandle) != 0U))
    {
      return;
    }

    if (osMessageQueuePut(sdLogQueueHandle, &packet, 0U, 0U) == osOK)
    {
      lastSdLogTick = now;
      g_sdLogQueuedFrames++;
    }
    else
    {
      g_sdLogDroppedFrames++;
    }
  }
}

static void SD_QueueCloseRequest(void)
{
  TelemetryFanoutPacket packet = {0};

  packet.closeRequest = 1U;
  if (sdLogQueueHandle == NULL)
  {
    return;
  }

  (void)osMessageQueueReset(sdLogQueueHandle);
  if (osMessageQueuePut(sdLogQueueHandle, &packet, 0U, 0U) != osOK)
  {
    g_sdLogDroppedFrames++;
  }
}

static void SD_QueueConfigSaveRequest(void)
{
  TelemetryFanoutPacket packet = {0};

  packet.configSaveRequest = 1U;
  if (sdLogQueueHandle == NULL)
  {
    return;
  }

  (void)osMessageQueueReset(sdLogQueueHandle);
  if (osMessageQueuePut(sdLogQueueHandle, &packet, 0U, 0U) != osOK)
  {
    g_sdLogDroppedFrames++;
  }
}

static void DisplayTelemetry_ProcessRxFrame(const CanRxFrame *frame)
{
  const DisplayTelemetryCanMessageConfig *messageConfig = NULL;
  ConfigMessage configMessage;

  if (frame == NULL)
  {
    return;
  }

  if (DisplayConfig_ParseCanFrame(frame, &configMessage) != 0U)
  {
    (void)Config_ApplyMessage(&configMessage);
    return;
  }

  messageConfig = DisplayTelemetryCanConfig_FindById(frame->header.Identifier);

  if ((frame->header.IdType == FDCAN_STANDARD_ID) &&
      (frame->header.RxFrameType == FDCAN_DATA_FRAME) &&
      (messageConfig != NULL) &&
      (frame->length >= messageConfig->minPayloadLength) &&
      (frame->length <= messageConfig->maxPayloadLength))
  {
    (void)DisplayTelemetry_ProcessCanFrame(messageConfig, frame->data, frame->length, frame->header.Identifier);
  }
}

void HAL_FDCAN_RxFifo0Callback(FDCAN_HandleTypeDef *hfdcan, uint32_t RxFifo0ITs)
{
  if ((hfdcan == NULL) ||
      ((hfdcan->Instance != FDCAN1) && (hfdcan->Instance != FDCAN2)) ||
      ((RxFifo0ITs & FDCAN_IT_RX_FIFO0_NEW_MESSAGE) == 0U))
  {
    return;
  }

  while (HAL_FDCAN_GetRxFifoFillLevel(hfdcan, FDCAN_RX_FIFO0) > 0U)
  {
    CanRxFrame frame = {0};

    if (HAL_FDCAN_GetRxMessage(hfdcan, FDCAN_RX_FIFO0, &frame.header, frame.data) != HAL_OK)
    {
      break;
    }

    frame.length = (uint8_t)DisplayTelemetry_DecodePayloadLength(frame.header.DataLength);
    frame.tick = HAL_GetTick();
    g_canRxIsrCount++;

    if (osMessageQueuePut(canRxQueueHandle, &frame, 0U, 0U) != osOK)
    {
      g_canRxDroppedFrames++;
    }
  }
}

static uint8_t DisplayConfig_ParseCanFrame(const CanRxFrame *frame, ConfigMessage *message)
{
  if ((frame == NULL) || (message == NULL))
  {
    return 0U;
  }

  if ((frame->header.Identifier != CAN_CONFIG_RX_ID) || (frame->length < 2U))
  {
    return 0U;
  }

  message->source = CONFIG_SOURCE_CAN;
  message->key = frame->data[0];
  message->value = frame->data[1];
  if (frame->length >= 4U)
  {
    message->value |= (uint16_t)((uint16_t)frame->data[2] << 8);
  }
  message->originId = frame->header.Identifier;
  message->tick = frame->tick;
  return 1U;
}

static uint8_t LocalConfig_Apply(const ConfigMessage *message)
{
  if (message == NULL)
  {
    return 0U;
  }

  switch (message->key)
  {
    case APP_CONFIG_KEY_SD_LOG_ENABLE:
      g_localConfig.sdLoggingEnabled = (message->value != 0U) ? 1U : 0U;
      if (g_localConfig.sdLoggingEnabled == 0U)
      {
        g_sdLogRecordingActive = 0U;
        g_sdLogCreateRequested = 0U;
        SD_QueueCloseRequest();
      }
      return 1U;

    default:
      return 0U;
  }
}

static uint8_t VehicleConfig_Apply(const ConfigMessage *message)
{
  uint8_t index;

  if ((message == NULL) || (VehicleConfig_KeyToAlertIndex(message->key, &index) == 0U))
  {
    return 0U;
  }

  g_vehicleConfig.alertThresholds[index] = VehicleConfig_ClampAlertValue(index, message->value);
  return 1U;
}

static uint8_t Config_ApplyMessage(const ConfigMessage *message)
{
  uint8_t applied = 0U;
  char buffer[96];

  if (message == NULL)
  {
    return 0U;
  }

  applied = LocalConfig_Apply(message);
  if (applied == 0U)
  {
    applied = VehicleConfig_Apply(message);
  }

  (void)snprintf(buffer,
                 sizeof(buffer),
                 "[CFG] src=%u key=%u value=%u applied=%u\r\n",
                 (unsigned)message->source,
                 (unsigned)message->key,
                 (unsigned)message->value,
                 (unsigned)applied);
  Debug_LogUart5(buffer);

  if (message->source == CONFIG_SOURCE_CAN)
  {
    Config_SendCanAck(message, applied);
  }

  if (applied != 0U)
  {
    SD_QueueConfigSaveRequest();
  }

  return applied;
}

static void Config_SendCanAck(const ConfigMessage *message, uint8_t applied)
{
  CanTxMessage txMessage;

  if (message == NULL)
  {
    return;
  }

  (void)memset(&txMessage, 0, sizeof(txMessage));
  CanTx_FillConfigHeader(&txMessage.header, CAN_CONFIG_TX_ID, FDCAN_DLC_BYTES_4);
  txMessage.length = 4U;
  txMessage.data[0] = message->key;
  txMessage.data[1] = (uint8_t)(message->value & 0xFFU);
  txMessage.data[2] = (uint8_t)((message->value >> 8) & 0xFFU);
  txMessage.data[3] = applied;
  CanTx_QueueMessage(&txMessage);
}

static void CanTx_QueueMessage(const CanTxMessage *message)
{
  if (message == NULL)
  {
    return;
  }

  if (osMessageQueuePut(canTxQueueHandle, message, 0U, 0U) != osOK)
  {
    g_canTxDroppedFrames++;
  }
}

static void CanTx_FillConfigHeader(FDCAN_TxHeaderTypeDef *header, uint32_t canId, uint32_t dlc)
{
  if (header == NULL)
  {
    return;
  }

  header->Identifier = canId;
  header->IdType = FDCAN_STANDARD_ID;
  header->TxFrameType = FDCAN_DATA_FRAME;
  header->DataLength = dlc;
  header->ErrorStateIndicator = FDCAN_ESI_ACTIVE;
  header->BitRateSwitch = FDCAN_BRS_OFF;
  header->FDFormat = FDCAN_CLASSIC_CAN;
  header->TxEventFifoControl = FDCAN_NO_TX_EVENTS;
  header->MessageMarker = 0U;
}

static uint8_t VehicleConfig_IsAlertIndexValid(uint8_t index)
{
  return (index < VEHICLE_CONFIG_ALERT_PARAM_COUNT) ? 1U : 0U;
}

static uint8_t VehicleConfig_AlertIndexToKey(uint8_t index)
{
  return (uint8_t)(APP_CONFIG_KEY_VEHICLE_ALERT_0 + index);
}

static uint8_t VehicleConfig_KeyToAlertIndex(uint8_t key, uint8_t *index)
{
  if ((index == NULL) ||
      (key < APP_CONFIG_KEY_VEHICLE_ALERT_0) ||
      (key > APP_CONFIG_KEY_VEHICLE_ALERT_4))
  {
    return 0U;
  }

  *index = (uint8_t)(key - APP_CONFIG_KEY_VEHICLE_ALERT_0);
  return 1U;
}

static uint16_t VehicleConfig_ClampAlertValue(uint8_t index, uint16_t value)
{
  static const uint16_t maxValues[VEHICLE_CONFIG_ALERT_PARAM_COUNT] =
  {
    VEHICLE_CONFIG_ALERT_0_MAX,
    VEHICLE_CONFIG_ALERT_1_MAX,
    VEHICLE_CONFIG_ALERT_2_MAX,
    VEHICLE_CONFIG_ALERT_3_MAX,
    VEHICLE_CONFIG_ALERT_4_MAX
  };

  if (VehicleConfig_IsAlertIndexValid(index) == 0U)
  {
    return 0U;
  }

  return (value > maxValues[index]) ? maxValues[index] : value;
}

uint8_t AppConfig_IsLocalSdLoggingEnabled(void)
{
  return g_localConfig.sdLoggingEnabled;
}

uint8_t AppConfig_IsSdLogRecordingActive(void)
{
  return g_sdLogRecordingActive;
}

uint8_t AppConfig_SetLocalSdLoggingEnabled(uint8_t enabled)
{
  ConfigMessage message = {0};

  message.source = CONFIG_SOURCE_LOCAL;
  message.key = APP_CONFIG_KEY_SD_LOG_ENABLE;
  message.value = (enabled != 0U) ? 1U : 0U;
  message.originId = 0U;
  message.tick = HAL_GetTick();
  return Config_ApplyMessage(&message);
}

void AppConfig_RequestNewSdLogSession(void)
{
  if (g_localConfig.sdLoggingEnabled == 0U)
  {
    return;
  }

  g_sdLogCreateRequested = 1U;
  g_sdLogRecordingActive = 0U;
  g_sdLogFilePath[0] = '\0';
  (void)snprintf(g_sdLogSessionId, sizeof(g_sdLogSessionId), "NOLOG");
  SD_QueueCloseRequest();
}

void AppConfig_CopySdLogSessionId(char *buffer, uint32_t bufferSize)
{
  if ((buffer == NULL) || (bufferSize == 0U))
  {
    return;
  }

  taskENTER_CRITICAL();
  (void)snprintf(buffer, bufferSize, "%s", g_sdLogSessionId);
  taskEXIT_CRITICAL();
}

void AppConfig_GetVehicleConfigParams(VehicleConfigParams *params)
{
  if (params == NULL)
  {
    return;
  }

  *params = *(const VehicleConfigParams *)(const void *)&g_vehicleConfig;
}

uint16_t AppConfig_GetVehicleAlertThreshold(uint8_t index)
{
  if (VehicleConfig_IsAlertIndexValid(index) == 0U)
  {
    return 0U;
  }

  return g_vehicleConfig.alertThresholds[index];
}

uint8_t AppConfig_SetVehicleAlertThreshold(uint8_t index, uint16_t value)
{
  ConfigMessage message = {0};
  uint8_t applied;

  if (VehicleConfig_IsAlertIndexValid(index) == 0U)
  {
    return 0U;
  }

  message.source = CONFIG_SOURCE_LOCAL;
  message.key = VehicleConfig_AlertIndexToKey(index);
  message.value = value;
  message.originId = 0U;
  message.tick = HAL_GetTick();
  applied = Config_ApplyMessage(&message);
  if (applied != 0U)
  {
    message.value = g_vehicleConfig.alertThresholds[index];
    (void)AppConfig_SendCanConfigU16(message.key, message.value);
  }

  return applied;
}

uint8_t AppConfig_SendCanConfigU8(uint8_t key, uint8_t value)
{
  CanTxMessage message = {0};

  CanTx_FillConfigHeader(&message.header, CAN_CONFIG_RX_ID, FDCAN_DLC_BYTES_2);
  message.length = 2U;
  message.data[0] = key;
  message.data[1] = value;
  CanTx_QueueMessage(&message);
  return 1U;
}

uint8_t AppConfig_SendCanConfigU16(uint8_t key, uint16_t value)
{
  CanTxMessage message = {0};

  CanTx_FillConfigHeader(&message.header, CAN_CONFIG_RX_ID, FDCAN_DLC_BYTES_4);
  message.length = 4U;
  message.data[0] = key;
  message.data[1] = (uint8_t)(value & 0xFFU);
  message.data[2] = (uint8_t)((value >> 8) & 0xFFU);
  message.data[3] = 0U;
  CanTx_QueueMessage(&message);
  return 1U;
}

void vApplicationStackOverflowHook(TaskHandle_t xTask, char *pcTaskName)
{
  (void)xTask;
  Debug_LogUart5("[RTOS] STACK OVERFLOW\r\n");
  if (pcTaskName != NULL)
  {
    Debug_LogUart5(pcTaskName);
    Debug_LogUart5("\r\n");
  }
  __disable_irq();
  for (;;)
  {
  }
}

void vApplicationMallocFailedHook(void)
{
  Debug_LogUart5("[RTOS] MALLOC FAILED\r\n");
  __disable_irq();
  for (;;)
  {
  }
}

/* USER CODE END Application */
